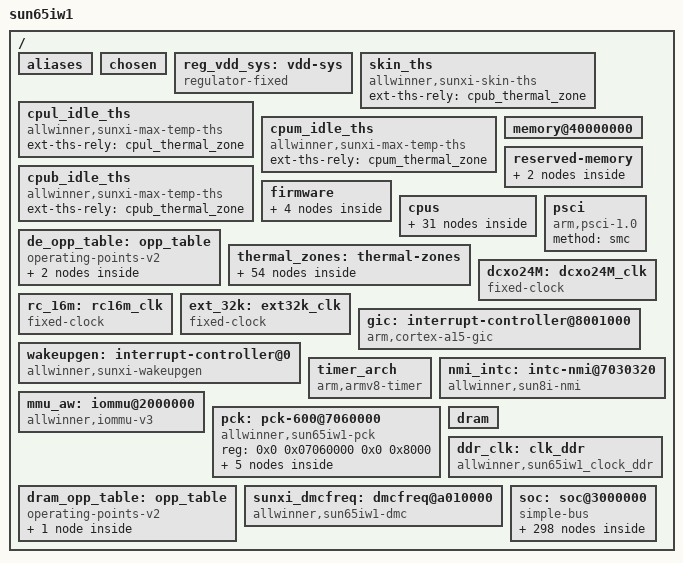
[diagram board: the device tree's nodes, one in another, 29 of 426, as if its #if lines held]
// SPDX-License-Identifier: (GPL-2.0+ or MIT)
#include <dt-bindings/clock/sun65iw1-ccu.h>
#include <dt-bindings/clock/sun65iw1-rtc.h>
#include <dt-bindings/clock/sun65iw1-r-ccu.h>
#include <dt-bindings/clock/sun65iw1-cpupll-ccu.h>
#include <dt-bindings/clock/sun65iw1-ddrpll-ccu.h>
#include <dt-bindings/clock/sunxi-ccu.h>
#include <dt-bindings/gpio/gpio.h>
#include <dt-bindings/gpio/sun4i-gpio.h>
#include <dt-bindings/reset/sun65iw1-ccu.h>
#include <dt-bindings/reset/sun65iw1-r-ccu.h>
#include <dt-bindings/power/sun65iw1-power.h>
#include <dt-bindings/interrupt-controller/arm-gic.h>
#include <dt-bindings/phy/phy.h>
#include <dt-bindings/thermal/thermal.h>
#include <dt-bindings/display/sunxi-lcd.h>
#include <dt-bindings/spi/sunxi-spi.h>
#include <dt-bindings/usb/pd.h>
#include "sun65iw1p1-vf.dtsi"

/ {
	model = "sun65iw1";
	interrupt-parent = <&wakeupgen>;
	#address-cells = <2>;
	#size-cells = <2>;

	aliases {
		serial0 = &uart0;
		serial1 = &uart1;
		serial2 = &uart2;
		serial3 = &uart3;
		serial4 = &uart4;
		serial5 = &uart5;
		serial6 = &uart6;
		serial7 = &uart7;
		serial8 = &uart8;
		serial9 = &uart9;
		ir0 = &ir_rx;
		ir1 = &s_ir_rx;
		spi0 = &spi0;
		spi1 = &spi1;
		spi2 = &spi2;
		spi3 = &r_spi0;
		twi0 = &twi0;
		twi1 = &twi1;
		twi2 = &twi2;
		twi3 = &twi3;
		twi4 = &twi4;
		twi5 = &twi5;
		twi6 = &s_twi0;
		twi7 = &s_twi1;
		twi8 = &s_twi2;
		pwm0 = &pwm0;
		pwm1 = &s_pwm0;
		ethernet0 = &gmac0;
		sunxi-mmc0 = &sdc0;
		sunxi-mmc2 = &sdc2;
		gpadc0 = &gpadc0;
		ve0 = &ve;
	};

	chosen {
		bootargs = "earlyprintk=sunxi-uart,0x2500000 loglevel=8 initcall_debug=0 console=ttyS0 init=/init";
		linux,initrd-start = <0x0 0x0>;
		linux,initrd-end = <0x0 0x0>;
		rng-seed;   /* This random value should be provided by bootloader */
		kaslr-seed; /* This random value should be provided by bootloader */
	};

	reg_vdd_sys: vdd-sys {
		compatible = "regulator-fixed";
		regulator-name = "vdd_sys";
		regulator-min-microvolt = <900000>;
		regulator-max-microvolt = <900000>;
		regulator-boot-on;
		regulator-always-on;
	};

	skin_ths: skin_ths {
		compatible = "allwinner,sunxi-skin-ths";
		ext-ths-rely = <&cpub_thermal_zone>;
		#thermal-sensor-cells = <0>;
		status = "okay";
	};

	cpul_idle_ths: cpul_idle_ths {
		compatible = "allwinner,sunxi-max-temp-ths";
		ext-ths-rely = <&cpul_thermal_zone>;
		#thermal-sensor-cells = <0>;
		status = "okay";
	};

	cpum_idle_ths: cpum_idle_ths {
		compatible = "allwinner,sunxi-max-temp-ths";
		ext-ths-rely = <&cpum_thermal_zone>;
		#thermal-sensor-cells = <0>;
		status = "okay";
	};

	cpub_idle_ths: cpub_idle_ths {
		compatible = "allwinner,sunxi-max-temp-ths";
		ext-ths-rely = <&cpub_thermal_zone>;
		#thermal-sensor-cells = <0>;
		status = "okay";
	};

	/* avoid panic when memory-node err(from uboot) */
	memory@40000000 {
		device_type = "memory";
		reg = <0x00000000 0x40000000 0x00000000 0x20000000>;
	};

	reserved-memory {
		#address-cells = <2>;
		#size-cells = <2>;
		ranges;

		bl31 {
			reg = <0x0 0x48000000 0x0 0x01000000>;
		};

#ifdef CONFIG_AW_DRM_DYNAMIC_REGION
		/*
		 * A 150MB memory region located below the 2GB address in DDR, with 4MB-aligned addr and size.
		 * start = (0x40000000+2G-152M), size = 152M.
		 * NOTE: Keep in sync with the param 'dram_region_mbytes' in sys_config.fex.
		 */
		drm_region: cma@b6800000 {
			compatible = "shared-dma-pool", "restricted-dma-pool";
			reg = <0x0 0xb6800000 0x0 0x9800000>;
			reusable;
		};
#endif
	};

	firmware {
		android {
			compatible = "android,firmware";
			name = "android";
			boot_devices = "soc@3000000/4008000.sdmmc,soc@3000000/400a000.sdmmc,soc@3000000";
			vbmeta {
				compatible = "android,vbmeta";
				parts = "vbmeta,vbmeta_system,vbmeta_vendor,boot,init_boot";
			};
		};

		optee {
			compatible = "linaro,optee-tz";
			method = "smc";
		};

#ifdef CONFIG_AW_DRM_DYNAMIC_REGION
		drm_heap_0: drm_heap {
			compatible = "allwinner,sunxi-drm-heap-v2";
			memory-region = <&drm_region>;
		};
#endif
	};

	cpus {
		#address-cells = <2>;
		#size-cells = <0>;

		cpu0: cpu@0 {
			device_type = "cpu";
			compatible = "arm,cortex-a53";
			reg = <0x0 0x0>;
			enable-method = "psci";
			next-level-cache = <&A53_L2_0>;
			cpu-idle-states = <&CLUSTER_SLEEP_0>;
			capacity-dmips-mhz = <592>;
			clocks = <&cpupll_ccu CLK_PLL_CPU0>;
			operating-points-v2 = <&cluster0_opp_table>;
			#cooling-cells = <2>;
			dynamic-power-coefficient = <57>;
		};

		cpu1: cpu@1 {
			device_type = "cpu";
			compatible = "arm,cortex-a53";
			reg = <0x0 0x1>;
			enable-method = "psci";
			next-level-cache = <&A53_L2_0>;
			cpu-idle-states = <&CLUSTER_SLEEP_0>;
			capacity-dmips-mhz = <592>;
			clocks = <&cpupll_ccu CLK_PLL_CPU0>;
			operating-points-v2 = <&cluster0_opp_table>;
			#cooling-cells = <2>;
		};

		cpu2: cpu@2 {
			device_type = "cpu";
			compatible = "arm,cortex-a53";
			reg = <0x0 0x2>;
			enable-method = "psci";
			next-level-cache = <&A53_L2_0>;
			cpu-idle-states = <&CLUSTER_SLEEP_0>;
			capacity-dmips-mhz = <592>;
			clocks = <&cpupll_ccu CLK_PLL_CPU0>;
			operating-points-v2 = <&cluster0_opp_table>;
			#cooling-cells = <2>;

			cpu2_idle: thermal-idle {
				#cooling-cells = <2>;
				duration-us = <10000>;
				exit-latency-us = <500>;
			};
		};

		cpu3: cpu@3 {
			device_type = "cpu";
			compatible = "arm,cortex-a53";
			reg = <0x0 0x3>;
			enable-method = "psci";
			next-level-cache = <&A53_L2_0>;
			cpu-idle-states = <&CLUSTER_SLEEP_0>;
			capacity-dmips-mhz = <592>;
			clocks = <&cpupll_ccu CLK_PLL_CPU0>;
			operating-points-v2 = <&cluster0_opp_table>;
			#cooling-cells = <2>;

			cpu3_idle: thermal-idle {
				#cooling-cells = <2>;
				duration-us = <10000>;
				exit-latency-us = <500>;
			};
		};

		cpu4: cpu@100 {
			device_type = "cpu";
			compatible = "arm,cortex-a53";
			reg = <0x0 0x100>;
			enable-method = "psci";
			next-level-cache = <&A53_L2_1>;
			cpu-idle-states = <&CLUSTER_SLEEP_0>;
			capacity-dmips-mhz = <592>;
			clocks = <&cpupll_ccu CLK_PLL_CPU1>;
			operating-points-v2 = <&cluster1_opp_table>;
			#cooling-cells = <2>;
			dynamic-power-coefficient = <60>;

			cpu4_idle: thermal-idle {
				#cooling-cells = <2>;
				duration-us = <10000>;
				exit-latency-us = <500>;
			};
		};

		cpu5: cpu@101 {
			device_type = "cpu";
			compatible = "arm,cortex-a53";
			reg = <0x0 0x101>;
			enable-method = "psci";
			next-level-cache = <&A53_L2_1>;
			cpu-idle-states = <&CLUSTER_SLEEP_0>;
			capacity-dmips-mhz = <592>;
			clocks = <&cpupll_ccu CLK_PLL_CPU1>;
			operating-points-v2 = <&cluster1_opp_table>;
			#cooling-cells = <2>;

			cpu5_idle: thermal-idle {
				#cooling-cells = <2>;
				duration-us = <10000>;
				exit-latency-us = <500>;
			};
		};

		cpu6: cpu@200 {
			device_type = "cpu";
			compatible = "arm,cortex-a73";
			reg = <0x0 0x200>;
			enable-method = "psci";
			next-level-cache = <&A73_L2>;
			cpu-idle-states = <&CLUSTER_SLEEP_0>;
			capacity-dmips-mhz = <1024>;
			clocks = <&cpupll_ccu CLK_PLL_CPU2>;
			operating-points-v2 = <&cluster2_opp_table>;
			#cooling-cells = <2>;
			dynamic-power-coefficient = <226>;

			cpu6_idle: thermal-idle {
				#cooling-cells = <2>;
				duration-us = <10000>;
				exit-latency-us = <500>;
			};
		};

		cpu7: cpu@201 {
			device_type = "cpu";
			compatible = "arm,cortex-a73";
			reg = <0x0 0x201>;
			enable-method = "psci";
			next-level-cache = <&A73_L2>;
			cpu-idle-states = <&CLUSTER_SLEEP_0>;
			capacity-dmips-mhz = <1024>;
			clocks = <&cpupll_ccu CLK_PLL_CPU2>;
			operating-points-v2 = <&cluster2_opp_table>;
			#cooling-cells = <2>;

			cpu7_idle: thermal-idle {
				#cooling-cells = <2>;
				duration-us = <10000>;
				exit-latency-us = <500>;
			};
		};

		cpu-map {
			cluster0 {
				core0 {
					cpu = <&cpu0>;
				};
				core1 {
					cpu = <&cpu1>;
				};
				core2 {
					cpu = <&cpu2>;
				};
				core3 {
					cpu = <&cpu3>;
				};
			};

			cluster1 {
				core0 {
					cpu = <&cpu4>;
				};
				core1 {
					cpu = <&cpu5>;
				};
			};

			cluster2 {
				core0 {
					cpu = <&cpu6>;
				};
				core1 {
					cpu = <&cpu7>;
				};
			};
		};

		idle-states {
			entry-method = "arm,psci";

			CLUSTER_SLEEP_0: cluster-sleep-0 {
				compatible = "arm,idle-state";
				arm,psci-suspend-param = <0x1010000>;
				entry-latency-us = <47>;
				exit-latency-us = <74>;
				min-residency-us = <5000>;
				local-timer-stop;
			};
		};

		A53_L2_0: l2-cache0 {
			compatible = "cache";
			cache-level = <2>;
			cache-unified;
		};

		A53_L2_1: l2-cache1 {
			compatible = "cache";
			cache-level = <2>;
			cache-unified;
		};

		A73_L2: l2-cache2 {
			compatible = "cache";
			cache-level = <2>;
			cache-unified;
		};
	};

	de_opp_table: opp_table {
		compatible = "operating-points-v2";

		opp@50000000 {
			opp-hz = /bits/ 64 <50000000>;
			opp-microvolt = <900000>;
		};

		opp@600000000 {
			opp-hz = /bits/ 64 <600000000>;
			opp-microvolt = <900000>;
		};
	};

	thermal_zones: thermal-zones {
		cpul_thermal_zone: cpul_thermal_zone {
			polling-delay-passive = <100>;
			polling-delay = <1000>;
			thermal-sensors = <&ths 0>;
			sustainable-power = <504>;

			cpul_trips: trips {
				cpul_threshold: trip-point@0 {
					temperature = <70000>;
					type = "passive";
					hysteresis = <2000>;
				};
				cpul_target: trip-point@1 {
					temperature = <90000>;
					type = "passive";
					hysteresis = <2000>;
				};
				cpul_crit: cpu_crit@0 {
					temperature = <110000>;
					type = "critical";
					hysteresis = <0>;
				};
			};

			cooling-maps {
				map0 {
					trip = <&cpul_target>;
					cooling-device = <&cpu0 THERMAL_NO_LIMIT THERMAL_NO_LIMIT>;
					contribution = <1024>;
				};
			};
		};

		cpum_thermal_zone: cpum_thermal_zone {
			polling-delay-passive = <100>;
			polling-delay = <1000>;
			thermal-sensors = <&ths 1>;
			sustainable-power = <210>;

			cpum_trips: trips {
				cpum_threshold: trip-point@0 {
					temperature = <70000>;
					type = "passive";
					hysteresis = <2000>;
				};
				cpum_target: trip-point@1 {
					temperature = <90000>;
					type = "passive";
					hysteresis = <2000>;
				};
				cpum_crit: cpu_crit@0 {
					temperature = <110000>;
					type = "critical";
					hysteresis = <0>;
				};
			};

			cooling-maps {
				map0 {
					trip = <&cpum_target>;
					cooling-device = <&cpu4 THERMAL_NO_LIMIT THERMAL_NO_LIMIT>;
					contribution = <1024>;
				};
			};
		};

		cpub_thermal_zone: cpub_thermal_zone {
			polling-delay-passive = <100>;
			polling-delay = <1000>;
			thermal-sensors = <&ths 2>;
			sustainable-power = <914>;

			cpub_trips: trips {
				cpub_threshold: trip-point@0 {
					temperature = <70000>;
					type = "passive";
					hysteresis = <2000>;
				};
				cpub_target: trip-point@1 {
					temperature = <90000>;
					type = "passive";
					hysteresis = <2000>;
				};
				cpub_crit: cpu_crit@0 {
					temperature = <110000>;
					type = "critical";
					hysteresis = <0>;
				};
			};

			cooling-maps {
				map0 {
					trip = <&cpub_target>;
					cooling-device = <&cpu6 THERMAL_NO_LIMIT THERMAL_NO_LIMIT>;
					contribution = <1024>;
				};
			};
		};

		gpu_thermal_zone: gpu_thermal_zone {
			polling-delay-passive = <100>;
			polling-delay = <1000>;
			thermal-sensors = <&ths 3>;

			gpu_trips: trips {
				gpu_threshold: trip-point@0 {
					temperature = <70000>;
					type = "passive";
					hysteresis = <0>;
				};
				gpu_target: trip-point@1 {
					temperature = <90000>;
					type = "passive";
					hysteresis = <0>;
				};
				gpu_crit: gpu_crit@0 {
					temperature = <110000>;
					type = "critical";
					hysteresis = <0>;
				};
			};

			cooling-maps {
				map0 {
					trip = <&gpu_threshold>;
					cooling-device = <&gpu 0 0>;
					contribution = <1024>;
				};
				map1 {
					trip = <&gpu_target>;
					cooling-device = <&gpu 0 THERMAL_NO_LIMIT>;
					contribution = <1024>;
				};
				map2 {
					trip = <&gpu_crit>;
					cooling-device = <&gpu THERMAL_NO_LIMIT THERMAL_NO_LIMIT>;
					contribution = <1024>;
				};
			};
		};

		ddr_thermal_zone: ddr_thermal_zone {
			polling-delay-passive = <100>;
			polling-delay = <1000>;
			thermal-sensors = <&ths 4>;

			ddr_trips: trips {
				ddr_crit: ddr_crit@0 {
					temperature = <110000>;
					type = "critical";
					hysteresis = <0>;
				};
			};
		};

		skin_zone: skin_zone {
			polling-delay-passive = <0>;
			polling-delay = <0>;
			thermal-sensors = <&skin_ths>;

			skin_trips: trips {
				skin_crit: skin_crit@0 {
					temperature = <50000>;
					type = "critical";
					hysteresis = <0>;
				};
			};
		};

		cpul_idle_zone: cpul_idle_zone {
			polling-delay-passive = <100>;
			polling-delay = <1000>;
			thermal-sensors = <&cpul_idle_ths>;

			cpul_idle_trips: trips {
				cpul_thres: trip-point@0 {
					temperature = <90000>;
					type = "passive";
					hysteresis = <2000>;
				};
				cpul_overshot: trip-point@1{
					temperature = <100000>;
					type = "passive";
					hysteresis = <2000>;
				};
			};

			cooling-maps {
				map0 {
					trip = <&cpul_overshot>;
					cooling-device = <&cpu2_idle 0 50>,
							 <&cpu3_idle 0 50>;
					contribution = <1024>;
				};
			};
		};

		cpum_idle_zone: cpum_idle_zone {
			polling-delay-passive = <100>;
			polling-delay = <1000>;
			thermal-sensors = <&cpum_idle_ths>;

			cpum_idle_trips: trips {
				cpum_thres: trip-point@0 {
					temperature = <90000>;
					type = "passive";
					hysteresis = <2000>;
				};
				cpum_overshot: trip-point@1{
					temperature = <100000>;
					type = "passive";
					hysteresis = <2000>;
				};
			};

			cooling-maps {
				map0 {
					trip = <&cpum_overshot>;
					cooling-device = <&cpu4_idle 0 50>,
							 <&cpu5_idle 0 50>;
					contribution = <1024>;
				};
			};
		};

		cpub_idle_zone: cpub_idle_zone {
			polling-delay-passive = <100>;
			polling-delay = <1000>;
			thermal-sensors = <&cpub_idle_ths>;

			cpub_idle_trips: trips {
				cpub_thres: trip-point@0 {
					temperature = <90000>;
					type = "passive";
					hysteresis = <2000>;
				};
				cpub_overshot: trip-point@1{
					temperature = <100000>;
					type = "passive";
					hysteresis = <2000>;
				};
			};

			cooling-maps {
				map0 {
					trip = <&cpub_overshot>;
					cooling-device = <&cpu6_idle 0 100>,
							 <&cpu7_idle 0 100>;
					contribution = <1024>;
				};
			};
		};
	};

	psci {
		compatible = "arm,psci-1.0";
		method = "smc";
	};

	dcxo24M: dcxo24M_clk {
		#clock-cells = <0>;
		compatible = "fixed-clock";
		clock-frequency = <24000000>;
		clock-output-names = "dcxo24M";
	};

	rc_16m: rc16m_clk {
		#clock-cells = <0>;
		compatible = "fixed-clock";
		clock-frequency = <16000000>;
		clock-accuracy = <300000000>;
		clock-output-names = "rc-16m";
	};

	ext_32k: ext32k_clk {
		#clock-cells = <0>;
		compatible = "fixed-clock";
		clock-frequency = <32768>;
		clock-output-names = "ext-32k";
	};

	gic: interrupt-controller@8001000{
		compatible = "arm,cortex-a15-gic", "arm,cortex-a9-gic";
		#interrupt-cells = <3>;
		#address-cells = <0>;
		device_type = "gic";
		interrupt-controller;
		reg = <0x0 0x08001000 0 0x1000>, /* GIC Dist */
			<0x0 0x08002000 0 0x2000>, /* GIC CPU */
			<0x0 0x08004000 0 0x2000>, /* GIC VCPU Control */
			<0x0 0x08006000 0 0x2000>; /* GIC VCPU */
		interrupts = <GIC_PPI 9 0xf04>; /* GIC Maintenence IRQ */
		interrupt-parent = <&gic>;
	};

	wakeupgen: interrupt-controller@0 {
		compatible = "allwinner,sunxi-wakeupgen";
		interrupt-controller;
		#interrupt-cells = <3>;
		#address-cells = <0>;
		interrupt-parent = <&gic>;
	};

	timer_arch {
		compatible = "arm,armv8-timer";
		interrupts = <GIC_PPI 13 (GIC_CPU_MASK_SIMPLE(4) | IRQ_TYPE_LEVEL_LOW)>,
			     <GIC_PPI 14 (GIC_CPU_MASK_SIMPLE(4) | IRQ_TYPE_LEVEL_LOW)>,
			     <GIC_PPI 11 (GIC_CPU_MASK_SIMPLE(4) | IRQ_TYPE_LEVEL_LOW)>,
			     <GIC_PPI 10 (GIC_CPU_MASK_SIMPLE(4) | IRQ_TYPE_LEVEL_LOW)>;
		clock-frequency = <24000000>;
		interrupt-parent = <&gic>;
		arm,no-tick-in-suspend;
	};

	nmi_intc: intc-nmi@7030320 {
		compatible = "allwinner,sun8i-nmi";
		interrupt-parent = <&gic>;
		#interrupt-cells = <2>;
		#address-cells = <0>;
		interrupt-controller;
		reg = <0x0 0x07030320 0 0xc>;
		interrupts = <GIC_SPI 224 IRQ_TYPE_LEVEL_HIGH>;
	};

	mmu_aw: iommu@2000000 {
		compatible = "allwinner,iommu-v3";
		reg = <0x0 0x02000000 0x0 0x1000>;
		interrupts = <GIC_SPI 91 IRQ_TYPE_LEVEL_HIGH>;
		interrupt-names = "iommu-irq";
		clocks = <&ccu CLK_BUS_IOMMU_APB>;
		clock-names = "iommu";
		/* clock-frequency = <24000000>; */
		#iommu-cells = <2>;
		version=<0x17>;
		tlb_prefetch = <0x3007f>;
		tlb_invalid_mode = <0x1>;
		ptw_invalid_mode = <0x1>;
		masters = "ISP", "CSI", "VE0", "Eink", "G2D",
			"DE", "RESERVED", "DEBUG_MODE";
		valid_masters=<7>;
	};

	pck: pck-600@7060000 {
		compatible = "allwinner,sun65iw1-pck", "syscon", "simple-mfd";
		reg = <0x0 0x07060000 0x0 0x8000>;

		pd: power-controller {
			compatible = "allwinner,sun65iw1-pck-600";
			clocks = <&r_ccu CLK_BUS_R_PPU_VO0>;
			clock-names = "pck";
			#power-domain-cells = <1>;
			#address-cells = <1>;
			#size-cells = <0>;

			pd_vo@SUN65IW1_PCK_VO {
				reg = <SUN65IW1_PCK_VO>;
			};

			pd_ve@SUN65IW1_PCK_VE {
				reg = <SUN65IW1_PCK_VE>;
			};

			pd_vi@SUN65IW1_PCK_VI {
				reg = <SUN65IW1_PCK_VI>;
			};

			pd_hsi@SUN65IW1_PCK_HSI {
				reg = <SUN65IW1_PCK_HSI>;
			};
		};
	};

	dram: dram {
		/* for uboot update dram para */
		dram_para00 = <0x00000000>;
		dram_para01 = <0x00000000>;
		dram_para02 = <0x00000000>;
		dram_para03 = <0x00000000>;
		dram_para04 = <0x00000000>;
		dram_para05 = <0x00000000>;
		dram_para06 = <0x00000000>;
		dram_para07 = <0x00000000>;
		dram_para08 = <0x00000000>;
		dram_para09 = <0x00000000>;
		dram_para10 = <0x00000000>;
		dram_para11 = <0x00000000>;
		dram_para12 = <0x00000000>;
		dram_para13 = <0x00000000>;
		dram_para14 = <0x00000000>;
		dram_para15 = <0x00000000>;
		dram_para16 = <0x00000000>;
		dram_para17 = <0x00000000>;
		dram_para18 = <0x00000000>;
		dram_para19 = <0x00000000>;
		dram_para20 = <0x00000000>;
		dram_para21 = <0x00000000>;
		dram_para22 = <0x00000000>;
		dram_para23 = <0x00000000>;
		dram_para24 = <0x00000000>;
		dram_para25 = <0x00000000>;
		dram_para26 = <0x00000000>;
		dram_para27 = <0x00000000>;
		dram_para28 = <0x00000000>;
		dram_para29 = <0x00000000>;
		dram_para30 = <0x00000000>;
		dram_para31 = <0x00000000>;
		dram_para32 = <0x00000000>;
		dram_para33 = <0x00000000>;
		dram_para34 = <0x00000000>;
		dram_para35 = <0x00000000>;
		dram_para36 = <0x00000000>;
		dram_para37 = <0x00000000>;
		dram_para38 = <0x00000000>;
		dram_para39 = <0x00000000>;
		dram_para40 = <0x00000000>;
		dram_para41 = <0x00000000>;
		dram_para42 = <0x00000000>;
		dram_para43 = <0x00000000>;
		dram_para44 = <0x00000000>;
		dram_para45 = <0x00000000>;
		dram_para46 = <0x00000000>;
		dram_para47 = <0x00000000>;
		dram_para48 = <0x00000000>;
		dram_para49 = <0x00000000>;
		dram_para50 = <0x00000000>;
		dram_para51 = <0x00000000>;
		dram_para52 = <0x00000000>;
		dram_para53 = <0x00000000>;
		dram_para54 = <0x00000000>;
		dram_para55 = <0x00000000>;
		dram_para56 = <0x00000000>;
		dram_para57 = <0x00000000>;
		dram_para58 = <0x00000000>;
		dram_para59 = <0x00000000>;
		dram_para60 = <0x00000000>;
		dram_para61 = <0x00000000>;
		dram_para62 = <0x00000000>;
		dram_para63 = <0x00000000>;
		dram_para64 = <0x00000000>;
		dram_para65 = <0x00000000>;
		dram_para66 = <0x00000000>;
		dram_para67 = <0x00000000>;
		dram_para68 = <0x00000000>;
		dram_para69 = <0x00000000>;
		dram_para70 = <0x00000000>;
		dram_para71 = <0x00000000>;
		dram_para72 = <0x00000000>;
		dram_para73 = <0x00000000>;
		dram_para74 = <0x00000000>;
		dram_para75 = <0x00000000>;
		dram_para76 = <0x00000000>;
		dram_para77 = <0x00000000>;
		dram_para78 = <0x00000000>;
		dram_para79 = <0x00000000>;
		dram_para80 = <0x00000000>;
		dram_para81 = <0x00000000>;
		dram_para82 = <0x00000000>;
		dram_para83 = <0x00000000>;
		dram_para84 = <0x00000000>;
		dram_para85 = <0x00000000>;
		dram_para86 = <0x00000000>;
		dram_para87 = <0x00000000>;
		dram_para88 = <0x00000000>;
		dram_para89 = <0x00000000>;
		dram_para90 = <0x00000000>;
		dram_para91 = <0x00000000>;
		dram_para92 = <0x00000000>;
		dram_para93 = <0x00000000>;
		dram_para94 = <0x00000000>;
		dram_para95 = <0x00000000>;
	};

	ddr_clk: clk_ddr {
		compatible = "allwinner,sun65iw1_clock_ddr";
		reg = <0x0 0x0a030000 0x0 0x1000>,
				<0x0 0x0a011000 0x0 0x1000>;
		clocks = <&drampll_ccu CLK_DFI>,
				<&drampll_ccu CLK_PLL_DDR0>,
				<&drampll_ccu CLK_PLL_DDR1>,
				<&drampll_ccu CLK_PLL_DDR2>;
		clock-names = "dfi_clk", "ddrpll0", "ddrpll1", "ddrpll2";
		#clock-cells = <0>;
	};

	dram_opp_table: opp_table {
		compatible = "operating-points-v2";
		opp@150000000 {
			opp-hz = /bits/ 64 <150000000>;
			clock-latency-ns = <150000>;
			opp-microvolt = <900000>;
		};
	};

	sunxi_dmcfreq: dmcfreq@a010000 {
		compatible = "allwinner,sun65iw1-dmc";
		reg = <0x0 0x0a010000 0x0 0x11000>,
			  <0x0 0x02400000 0x0 0x3000>;
		interrupts = <GIC_SPI 88 IRQ_TYPE_LEVEL_HIGH>;
		clocks = <&ddr_clk>,
				<&ccu CLK_NSI>,
				<&drampll_ccu CLK_PLL_DDR0>,
				<&drampll_ccu CLK_PLL_DDR1>,
				<&drampll_ccu CLK_PLL_DDR2>;
		clock-names = "dram", "bus", "ddrpll0", "ddrpll1", "ddrpll2";
		operating-points-v2 = <&dram_opp_table>;
		upthreshold = <30>;
		downdifferential = <15>;
		vddcore-supply = <&reg_vdd_sys>;
		normalvoltage = <900000>;
		boostvoltage = <900000>;
	};

	soc: soc@3000000 {
		compatible = "simple-bus";
		#address-cells = <2>;
		#size-cells = <2>;
		ranges;

		cpufreq_hw: cpufreq@7010000 {
			compatible = "allwinner,sun65iw1-hw-dvfs";
			reg = <0 0x07010000 0 0x64>, <0 0x07010200 0 0x64>, <0 0x07010100 0 0x64>;
			reg-names = "cluster0-dvfs", "cluster1-dvfs", "cluster2-dvfs";
			clocks = <&cpupll_ccu CLK_PLL_CPU0>, <&cpupll_ccu CLK_PLL_CPU1>, <&cpupll_ccu CLK_PLL_CPU2>;
			#freq-domain-cells = <2>;
			dvfs_twi = <&s_twi0>;
			pmu_addr = <0x35 0x36 0x36>; //0x68 0x6c 0x6c
			pmu_reg_addr = <0x83 0x14 0x13>;
			twi_priority = <0 0 0>;
			twi_mask = <0x80 0x80 0x00>;
			channel = <0 1 2>;
			twi_channel_num = <3>;
			cluster0-supply = <&reg_dcdc1>;
			cluster1-supply = <&reg_axp1530_dcdc2>;
			cluster2-supply = <&reg_axp1530_dcdc1>;
		};

		rtc_ccu: rtc_ccu@7200000 {
			compatible = "allwinner,sun65iw1-rtc-ccu";
			reg = <0x0 0x07200000 0x0 0x400>;
			#clock-cells = <1>;
			#reset-cells = <1>;
		};

		cpupll_ccu: clock@8200000 {
			compatible = "allwinner,sun65iw1-cpupll";
			reg = <0x0 0x08200000 0x0 0x050c>;
			#clock-cells = <1>;
			#reset-cells = <1>;
			pll_step = <0x9>;
			pll_ssc = <0x3300>;
		};

		ccu: ccu@3008000 {
			compatible = "allwinner,sun65iw1-ccu";
			reg = <0x0 0x03008000 0x0 0x2000>;
			clocks = <&dcxo24M>, <&rtc_ccu CLK_OSC32K>, <&rc_16m>;
			clock-names = "hosc", "losc", "iosc";
			#clock-cells = <1>;
			#reset-cells = <1>;
		       /*
			* for example:
			* sdm_info: sdm_info {
			*	pll-video0-parent {
			*		sdm-enable = <1>; // required
			*		sdm-factor = <4>; // required
			*		freq-mode  = <TR_N>; // optional: default TR_N
			*		sdm-freq   = <FREQ_32>; // optional: default FREQ_31_5
			*	};
			* };
			*/
		};

		r_ccu: r_ccu@7030000 {
			compatible = "allwinner,sun65iw1-r-ccu";
			reg = <0x0 0x07030000 0x0 0x230>;
			#clock-cells = <1>;
			#reset-cells = <1>;
		};

		drampll_ccu: drampll_ccu@A030000 {
			compatible = "allwinner,sun65iw1-pll-dram";
			reg = <0x0 0x0A030000 0x0 0x1000>;
			#clock-cells = <1>;
			#reset-cells = <1>;
		};


		pd_vo_pwrctl: pd_vo_pwrctl@0 {
			compatible = "allwinner,sunxi-power-domain-power-ctl";
			power-domains = <&pd SUN65IW1_PCK_VO>;
			status = "okay";
		};

		pd_ve_pwrctl: pd_ve_pwrctl@0 {
			compatible = "allwinner,sunxi-power-domain-power-ctl";
			power-domains = <&pd SUN65IW1_PCK_VE>;
			status = "okay";
		};

		pd_vi_pwrctl: pd_vi_pwrctl@0 {
			compatible = "allwinner,sunxi-power-domain-power-ctl";
			power-domains = <&pd SUN65IW1_PCK_VI>;
			status = "okay";
		};

		/*
		pd_hsi_pwrctl: pd_hsi_pwrctl@0 {
			compatible = "allwinner,sunxi-power-domain-power-ctl";
			power-domains = <&pd SUN65IW1_PCK_HSI>;
			status = "okay";
		};
		*/

		ve: ve@1c0e000 {
			compatible = "allwinner,sunxi-cedar-ve";
			reg = <0x0 0x01c0e000 0x0 0x1000>,
				  <0x0 0x03200000 0x0 0x10>;
			interrupts = <GIC_SPI 182 IRQ_TYPE_LEVEL_HIGH>;
			clocks = <&ccu CLK_PLL_VE>,
				 <&ccu CLK_MBUS_VE0>,
				 <&ccu CLK_BUS_VE0_AHB_SW>,
				 <&ccu CLK_VE0_MBUS_GATE>,
				 <&ccu CLK_VE0>,
				 <&ccu CLK_BUS_VE0_AHB>;
			clock-names = "pll_ve",
				      "mbus_ve",
				      "ahb_gate",
				      "mbus_gate",
				      "ve",
				      "bus_ve";
			resets = <&ccu RST_BUS_VE0>;
			reset-names = "reset_ve";
			operating-points-v2 = <&ve_opp_table>;
			iommus = <&mmu_aw 2 1>;
			power-domains = <&pd SUN65IW1_PCK_VE>;
		};

		pio: pinctrl@3000000 {
			compatible = "allwinner,sun65iw1-pinctrl";
			reg = <0x0 0x03000000 0x0 0x800>;
			interrupts = <GIC_SPI 126 IRQ_TYPE_LEVEL_HIGH>,
				     <GIC_SPI 128 IRQ_TYPE_LEVEL_HIGH>,
				     <GIC_SPI 130 IRQ_TYPE_LEVEL_HIGH>,
				     <GIC_SPI 132 IRQ_TYPE_LEVEL_HIGH>,
				     <GIC_SPI 134 IRQ_TYPE_LEVEL_HIGH>,
				     <GIC_SPI 136 IRQ_TYPE_LEVEL_HIGH>,
				     <GIC_SPI 138 IRQ_TYPE_LEVEL_HIGH>,
				     <GIC_SPI 144 IRQ_TYPE_LEVEL_HIGH>;
			clocks = <&ccu CLK_APB1>, <&dcxo24M>, <&rtc_ccu CLK_OSC32K>;
			clock-names = "apb", "hosc", "losc";
			gpio-controller;
			#gpio-cells = <3>;
			interrupt-controller;
			#interrupt-cells = <3>;

			sdc0_pins_f: sdc0@5 {
				pins = "PF2";
				function = "sdc0";
				drive-strength = <40>;
				bias-pull-up;
				power-source = <3300>;
			};

			sdc0_pins_g: sdc0@6 {
				pins = "PF2";
				function = "sdc0";
				drive-strength = <40>;
				bias-pull-up;
				power-source = <1800>;
			};

			sdc0_pins_a: sdc0@0 {
				pins = "PF0", "PF1",
						"PF3", "PF4", "PF5";
				function = "sdc0";
				drive-strength = <20>;
				bias-pull-up;
				power-source = <3300>;
			};

			sdc0_pins_b: sdc0@1 {
				pins = "PF0", "PF1",
						"PF3", "PF4", "PF5";
				function = "sdc0";
				drive-strength = <20>;
				bias-pull-up;
				power-source = <1800>;
			};

			sdc0_pins_c: sdc0@2 {
				pins = "PF0", "PF1", "PF2",
				"PF3", "PF4", "PF5";
				function = "gpio_in";
			};

			/* TODO: add jtag pin */
			sdc0_pins_d: sdc0@3 {
				pins = "PF2", "PF4";
				function = "uart0";
				drive-strength = <10>;
				bias-pull-up;
			};

			sdc0_pins_e: sdc0@4 {
				pins = "PF0", "PF1", "PF3",
						"PF5";
				function = "jtag";
				drive-strength = <10>;
				bias-pull-up;
			};

			sdc1_pins_a: sdc1@0 {
				pins = "PG1", "PG2",
						"PG3", "PG4", "PG5";
				function = "sdc1";
				drive-strength = <20>;
				bias-pull-up;
			};

			sdc1_pins_b: sdc1@1 {
				pins = "PG0", "PG1", "PG2",
						"PG3", "PG4", "PG5";
				function = "gpio_in";
			};

			sdc1_pins_c: sdc1@2 {
				pins = "PG0";
				function = "sdc1";
				drive-strength = <40>;
				bias-pull-up;
			};

			sdc2_pins_a: sdc2@0 {
				pins = "PC3",
					"PC4", "PC5", "PC6", "PC7",
					"PC8", "PC9", "PC10", "PC11";
				function = "sdc2";
				drive-strength = <20>;
				bias-pull-up;
			};

			sdc2_pins_b: sdc2@1 {
				pins = "PC0", "PC1", "PC2", "PC3",
						"PC4", "PC5", "PC6", "PC7",
						"PC8", "PC9", "PC10", "PC11";
				function = "gpio_in";
			};

			sdc2_pins_c: sdc2@2 {
				pins = "PC0";
				function = "sdc2";
				drive-strength = <40>;
				bias-pull-down;
			};

			sdc2_pins_d: sdc2@3 {
				pins = "PC1", "PC2";
				function = "sdc2";
				drive-strength = <40>;
				bias-pull-up;
			};

			csi_mclk0_pins_a: csi_mclk0@0 {
				pins = "PE0";
				function = "mcsi0";
				drive-strength = <20>;
			};

			csi_mclk0_pins_b: csi_mclk0@1 {
				pins = "PE0";
				function = "gpio_in";
			};

			csi_mclk1_pins_a: csi_mclk1@0 {
				pins = "PE5";
				function = "mcsi1";
				drive-strength = <20>;
			};

			csi_mclk1_pins_b: csi_mclk1@1 {
				pins = "PE5";
				function = "gpio_in";
			};

			csi_mclk2_pins_a: csi_mclk2@0 {
				pins = "PE15";
				function = "mcsi2";
				drive-strength = <20>;
			};

			csi_mclk2_pins_b: csi_mclk2@1 {
				pins = "PE15";
				function = "gpio_in";
			};

			ncsi_bt656_pins_a: ncsi_BT656@0 {
				pins = "PK10", "PK12", "PK13",
				"PK14", "PK15", "PK16", "PK17",
				"PK18", "PK19", "PK20", "PK21";
				function = "ncsi";
				drive-strength = <20>;
			};

			ncsi_bt656_pins_b: ncsi_BT656@1 {
				pins = "PK10", "PK12", "PK13",
				"PK14", "PK15", "PK16", "PK17",
				"PK18", "PK19", "PK20", "PK21";
				function = "gpio_in";
			};

			ncsi_bt1120_pins_a: ncsi_BT1120@0 {
				pins = "PK10", "PK12", "PK13",
				"PK14", "PK15", "PK16", "PK17",
				"PK18", "PK19", "PK20", "PK21",
				"PE8", "PE9", "PE10", "PE11",
				"PE12", "PE13", "PE14", "PE15";
				function = "ncsi";
				drive-strength = <20>;
			};

			ncsi_bt1120_pins_b: ncsi_BT1120@1 {
				pins = "PK10", "PK12", "PK13",
				"PK14", "PK15", "PK16", "PK17",
				"PK18", "PK19", "PK20", "PK21",
				"PE8", "PE9", "PE10", "PE11",
				"PE12", "PE13", "PE14", "PE15";
				function = "gpio_in";
			};

			mipia_pins_a: mipia@0 {
				pins = "PK0", "PK1", "PK2", "PK3", "PK4", "PK5",
					"PK6", "PK7", "PK8", "PK9";
				function = "mcsia";
				drive-strength = <10>;
			};

			mipia_pins_b: mipia@1 {
				pins = "PK0", "PK1", "PK2", "PK3", "PK4", "PK5",
					"PK6", "PK7", "PK8", "PK9";
				function = "gpio_in";
			};

			mipib_pins_a: mipib@0 {
				pins = "PK10", "PK11", "PK12",
					"PK13", "PK14", "PK15";
				function = "mcsib";
				drive-strength = <10>;
			};

			mipib_pins_b: mipib@1 {
				pins = "PK10", "PK11", "PK12",
					"PK13", "PK14", "PK15";
				function = "gpio_in";
			};

			mipic_pins_a: mipic@0 {
				pins = "PK16", "PK17", "PK18",
					"PK19", "PK20", "PK21";
				function = "mcsic";
				drive-strength = <10>;
			};

			mipic_pins_b: mipic@1 {
				pins = "PK16", "PK17", "PK18",
					"PK19", "PK20", "PK21";
				function = "gpio_in";
			};

			mipic_4lane_pins_a: mipic_4lane@0 {
				pins = "PK16", "PK17", "PK18",
					"PK19", "PK20", "PK21";
				function = "mcsic";
				drive-strength = <10>;
			};

			mipic_4lane_pins_b: mipic_4lane@1 {
				pins = "PK16", "PK17", "PK18",
					"PK19", "PK20", "PK21";
				function = "gpio_in";
			};

			dsi0_4lane_pins_a: dsi0_4lane@0 {
				pins = "PD0", "PD1", "PD2", "PD3", "PD4", "PD5", "PD6", "PD7", "PD8", "PD9";
				function = "dsi0";
				drive-strength = <30>;
				bias-disable;
			};

			dsi0_4lane_pins_b: dsi0_4lane@1 {
				pins = "PD0", "PD1", "PD2", "PD3", "PD4", "PD5", "PD6", "PD7", "PD8", "PD9";
				function = "io_disabled";
				bias-disable;
			};

			lvds0_pins_a: lvds0@0 {
				pins = "PD0", "PD1", "PD2", "PD3", "PD4", "PD5", "PD6", "PD7", "PD8", "PD9";
				function = "lvds0";
				drive-strength = <30>;
			};

			lvds0_pins_b: lvds0@1 {
				pins = "PD0", "PD1", "PD2", "PD3", "PD4", "PD5", "PD6", "PD7", "PD8", "PD9";
				function = "gpio_in";
			};

			lvds1_pins_a: lvds1@0 {
				pins = "PD10", "PD11", "PD12", "PD13", "PD14", "PD15", "PD16", "PD17", "PD18", "PD19";
				function = "lvds1";
				drive-strength = <30>;
			};

			lvds1_pins_b: lvds1@1 {
				pins = "PD10", "PD11", "PD12", "PD13", "PD14", "PD15", "PD16", "PD17", "PD18", "PD19";
				function = "gpio_in";
			};

			rgb0_24pins_a: rgb0@0 {
				pins = "PH8", "PH9", "PD0", "PD1", "PD2", "PD3", "PD4", "PD5", "PH10", "PH13", "PD6", "PD7", "PD8", "PD9", \
					"PD10", "PD11", "PH14", "PH15", "PD12", "PD13", "PD14", "PD15", "PD16", "PD17", "PD18", "PD19", \
					"PD20", "PD21";
				function = "lcd0";
				drive-strength = <30>;
			};

			rgb0_24pins_b: rgb0@1 {
				pins = "PH8", "PH9", "PD0", "PD1", "PD2", "PD3", "PD4", "PD5", "PH10", "PH13", "PD6", "PD7", "PD8", "PD9", \
					"PD10", "PD11", "PH14", "PH15", "PD12", "PD13", "PD14", "PD15", "PD16", "PD17", "PD18", "PD19", \
					"PD20", "PD21";
				function = "gpio_in";
			};
		};

		r_pio: pinctrl@7058000 {
			#address-cells = <1>;
			compatible = "allwinner,sun65iw1-r-pinctrl";
			reg = <0x0 0x07058000 0x0 0x200>;
			interrupts = <GIC_SPI 234 IRQ_TYPE_LEVEL_HIGH>, /* GPIOL */
				<GIC_SPI 236 IRQ_TYPE_LEVEL_HIGH>;
			clocks = <&r_ccu CLK_R_APB0>, <&dcxo24M>, <&rtc_ccu CLK_OSC32K>;
			clock-names = "apb", "hosc", "losc";
			gpio-controller;
			#gpio-cells = <3>;
			interrupt-controller;
			#interrupt-cells = <3>;
		};

		uart0: uart@2B00000 {
			compatible = "allwinner,uart-v102";
			reg = <0x0 0x02B00000 0x0 0x400>;
			interrupts = <GIC_SPI 2 IRQ_TYPE_LEVEL_HIGH>;
			clocks = <&ccu CLK_BUS_UART0_APB>;
			resets = <&ccu RST_BUS_UART0>;
			sunxi,uart-fifosize = <64>;
			uart0_port = <0>;
			uart0_type = <2>;
		};

		uart1: uart@2B01000 {
			compatible = "allwinner,uart-v102";
			device_type = "uart1";
			reg = <0x0 0x02B01000 0x0 0x400>;
			interrupts = <GIC_SPI 3 IRQ_TYPE_LEVEL_HIGH>;
			clocks = <&ccu CLK_BUS_UART1_APB>;
			resets = <&ccu RST_BUS_UART1>;
			sunxi,uart-fifosize = <128>;
			uart1_port = <1>;
			uart1_type = <4>;
			dmas = <&dma 41>,<&dma 41>;
			dma-names = "fake_tx","fake_rx";
			//dma-names = "tx","rx";
			status = "disabled";
		};

		uart2: uart@2B02000 {
			compatible = "allwinner,uart-v102";
			device_type = "uart2";
			reg = <0x0 0x02B02000 0x0 0x400>;
			interrupts = <GIC_SPI 4 IRQ_TYPE_LEVEL_HIGH>;
			clocks = <&ccu CLK_BUS_UART2_APB>;
			resets = <&ccu RST_BUS_UART2>;
			sunxi,uart-fifosize = <128>;
			uart2_port = <2>;
			uart2_type = <4>;
			dmas = <&dma 42>,<&dma 42>;
			dma-names = "fake_tx","fake_rx";
			//dma-names = "tx","rx";
			status = "disabled";
		};

		uart3: uart@2B03000 {
			compatible = "allwinner,uart-v102";
			device_type = "uart3";
			reg = <0x0 0x02B03000 0x0 0x400>;
			interrupts = <GIC_SPI 5 IRQ_TYPE_LEVEL_HIGH>;
			clocks = <&ccu CLK_BUS_UART3_APB>;
			resets = <&ccu RST_BUS_UART3>;
			sunxi,uart-fifosize = <128>;
			uart3_port = <3>;
			uart3_type = <4>;
			dmas = <&dma 43>,<&dma 43>;
			dma-names = "fake_tx","fake_rx";
			//dma-names = "tx","rx";
			status = "disabled";
		};

		uart4: uart@2B04000 {
			compatible = "allwinner,uart-v102";
			device_type = "uart4";
			reg = <0x0 0x02B04000 0x0 0x400>;
			interrupts = <GIC_SPI 6 IRQ_TYPE_LEVEL_HIGH>;
			clocks = <&ccu CLK_BUS_UART4_APB>;
			resets = <&ccu RST_BUS_UART4>;
			sunxi,uart-fifosize = <128>;
			uart4_port = <4>;
			uart4_type = <4>;
			dmas = <&dma 44>,<&dma 44>;
			dma-names = "fake_tx","fake_rx";
			//dma-names = "tx","rx";
			status = "disabled";
		};

		uart5: uart@2B05000 {
			compatible = "allwinner,uart-v102";
			device_type = "uart5";
			reg = <0x0 0x02B05000 0x0 0x400>;
			interrupts = <GIC_SPI 7 IRQ_TYPE_LEVEL_HIGH>;
			clocks = <&ccu CLK_BUS_UART5_APB>;
			resets = <&ccu RST_BUS_UART5>;
			sunxi,uart-fifosize = <128>;
			uart5_port = <5>;
			uart5_type = <4>;
			dmas = <&dma 45>,<&dma 45>;
			dma-names = "fake_tx","fake_rx";
			//dma-names = "tx","rx";
			status = "disabled";
		};

		uart6: uart@2B06000 {
			compatible = "allwinner,uart-v102";
			device_type = "uart6";
			reg = <0x0 0x02B06000 0x0 0x400>;
			interrupts = <GIC_SPI 8 IRQ_TYPE_LEVEL_HIGH>;
			clocks = <&ccu CLK_BUS_UART6_APB>;
			resets = <&ccu RST_BUS_UART6>;
			sunxi,uart-fifosize = <128>;
			uart6_port = <6>;
			uart6_type = <4>;
			dmas = <&dma 46>,<&dma 46>;
			dma-names = "fake_tx","fake_rx";
			//dma-names = "tx","rx";
			status = "disabled";
		};

		uart7: uart@2B07000 {
			compatible = "allwinner,uart-v102";
			device_type = "uart7";
			reg = <0x0 0x02B07000 0x0 0x400>;
			interrupts = <GIC_SPI 9 IRQ_TYPE_LEVEL_HIGH>;
			clocks = <&ccu CLK_BUS_UART7_APB>;
			resets = <&ccu RST_BUS_UART7>;
			sunxi,uart-fifosize = <128>;
			uart7_port = <7>;
			uart7_type = <4>;
			dmas = <&dma 47>,<&dma 47>;
			dma-names = "fake_tx","fake_rx";
			//dma-names = "tx","rx";
			status = "disabled";
		};

		uart8: uart@7100000 {
			compatible = "allwinner,uart-v102";
			device_type = "uart8";
			reg = <0x0 0x07100000 0x0 0x400>;
			interrupts = <GIC_SPI 237 IRQ_TYPE_LEVEL_HIGH>;
			clocks = <&r_ccu CLK_BUS_R_UART0>;
			resets = <&r_ccu RST_BUS_R_UART0>;
			sunxi,uart-fifosize = <64>;
			uart8_port = <8>;
			uart8_type = <2>;
			dmas = <&dma 59>,<&dma 59>;
			dma-names = "fake_tx","fake_rx";
			//dma-names = "tx","rx";
			status = "disabled";
		};

		uart9: uart@7101000 {
			compatible = "allwinner,uart-v102";
			device_type = "uart9";
			reg = <0x0 0x07101000 0x0 0x400>;
			interrupts = <GIC_SPI 238 IRQ_TYPE_LEVEL_HIGH>;
			clocks = <&r_ccu CLK_BUS_R_UART1>;
			resets = <&r_ccu RST_BUS_R_UART1>;
			sunxi,uart-fifosize = <64>;
			uart9_port = <9>;
			uart9_type = <2>;
			dmas = <&dma 60>,<&dma 60>;
			dma-names = "fake_tx","fake_rx";
			//dma-names = "tx","rx";
			status = "disabled";
		};

		rtc: rtc@7200000 {
			compatible = "allwinner,rtc-v201";
			device_type = "rtc";
			wakeup-source;
			reg = <0x0 0x07200000 0x0 0x320>;
			interrupts = <GIC_SPI 232 IRQ_TYPE_LEVEL_HIGH>;
			clocks = <&r_ccu CLK_BUS_R_RTC>, <&rtc_ccu CLK_RTC_1K>, <&rtc_ccu CLK_RTC_SPI>;
			clock-names = "r-ahb-rtc", "rtc-1k", "rtc-spi";
			resets = <&r_ccu RST_BUS_RTC>;
			gpr_cur_pos = <6>;
			gpr_bootcount_pos = <7>;
		};

		ir_tx: ir_tx@2800000 {
			compatible = "allwinner,irtx";
			reg = <0x0 0x02800000 0x0 0x400>;
			interrupts = <GIC_SPI 30 IRQ_TYPE_LEVEL_HIGH>;
			clocks = <&ccu CLK_BUS_IR_TX_APB>, <&dcxo24M>, <&ccu CLK_IR_TX>;
			clock-names = "bus", "pclk", "mclk";
			resets = <&ccu RST_BUS_IR_TX>;
			status = "disabled";
		};

		ir_rx: ir_rx@2808000 {
			compatible = "allwinner,irrx";
			reg = <0x0 0x02808000 0x0 0x400>;
			interrupts = <GIC_SPI 31 IRQ_TYPE_LEVEL_HIGH>;
			clocks = <&ccu CLK_BUS_IR_RX0_APB>, <&dcxo24M>, <&ccu CLK_IR_RX0>;
			clock-names = "bus", "pclk", "mclk";
			resets = <&ccu RST_BUS_IR_RX0>;
			status = "disabled";
		};

		s_ir_rx: s_ir_rx@70a8000 {
			compatible = "allwinner,irrx";
			reg = <0x0 0x070a8000 0x0 0x400>;
			interrupts = <GIC_SPI 242 IRQ_TYPE_LEVEL_HIGH>;
			clocks = <&r_ccu CLK_BUS_R_IR_RX>, <&dcxo24M>, <&r_ccu CLK_R_IR_RX>;
			clock-names = "bus", "pclk", "mclk";
			resets = <&r_ccu RST_BUS_R_IR_RX>;
			status = "disabled";
		};

		s_twi0: s_twi0@7108000 {
			#address-cells = <1>;
			#size-cells = <0>;
			compatible = "allwinner,sunxi-twi-v103";
			device_type = "s_twi0";
			reg = <0x0 0x07108000 0x0 0x400>;
			interrupts = <GIC_SPI 239 IRQ_TYPE_LEVEL_HIGH>;
			clocks = <&r_ccu CLK_BUS_R_TWI0>, <&r_ccu CLK_R_APB1>;
			clock-names = "bus", "apb";
			resets = <&r_ccu RST_BUS_R_TWI0>;
			dmas = <&dma 56>, <&dma 56>;
			dma-names = "tx", "rx";
			twi_dvfs_enable;
			status = "disabled";
		};

		s_twi1: s_twi1@7109000 {
			#address-cells = <1>;
			#size-cells = <0>;
			compatible = "allwinner,sunxi-twi-v102";
			device_type = "s_twi1";
			reg = <0x0 0x07109000 0x0 0x400>;
			interrupts = <GIC_SPI 240 IRQ_TYPE_LEVEL_HIGH>;
			clocks = <&r_ccu CLK_BUS_R_TWI1>, <&r_ccu CLK_R_APB1>;
			clock-names = "bus", "apb";
			resets = <&r_ccu RST_BUS_R_TWI1>;
			dmas = <&dma 57>, <&dma 57>;
			dma-names = "tx", "rx";
			status = "disabled";
		};

		s_twi2: s_twi2@710a000 {
			#address-cells = <1>;
			#size-cells = <0>;
			compatible = "allwinner,sunxi-twi-v102";
			device_type = "s_twi2";
			reg = <0x0 0x0710a000 0x0 0x400>;
			interrupts = <GIC_SPI 241 IRQ_TYPE_LEVEL_HIGH>;
			clocks = <&r_ccu CLK_BUS_R_TWI2>, <&r_ccu CLK_R_APB1>;
			clock-names = "bus", "apb";
			resets = <&r_ccu RST_BUS_R_TWI2>;
			dmas = <&dma 58>, <&dma 58>;
			dma-names = "tx", "rx";
			status = "disabled";
		};

		twi0: twi0@2a00000 {
			#address-cells = <1>;
			#size-cells = <0>;
			compatible = "allwinner,sunxi-twi-v102";
			device_type = "twi0";
			reg = <0x0 0x02a00000 0x0 0x400>;
			interrupts = <GIC_SPI 10 IRQ_TYPE_LEVEL_HIGH>;
			clocks = <&ccu CLK_BUS_TWI0_APB>, <&ccu CLK_APB1>;
			clock-names = "bus", "apb";
			resets = <&ccu RST_BUS_TWI0>;
			dmas = <&dma 14>, <&dma 14>;
			dma-names = "tx", "rx";
			status = "disabled";
		};

		twi1: twi1@2a01000 {
			#address-cells = <1>;
			#size-cells = <0>;
			compatible = "allwinner,sunxi-twi-v102";
			device_type = "twi1";
			reg = <0x0 0x02a01000 0x0 0x400>;
			interrupts = <GIC_SPI 11 IRQ_TYPE_LEVEL_HIGH>;
			clocks = <&ccu CLK_BUS_TWI1_APB>, <&ccu CLK_APB1>;
			clock-names = "bus", "apb";
			resets = <&ccu RST_BUS_TWI1>;
			dmas = <&dma 15>, <&dma 15>;
			dma-names = "tx", "rx";
			status = "disabled";
		};

		twi2: twi2@2a02000 {
			#address-cells = <1>;
			#size-cells = <0>;
			compatible = "allwinner,sunxi-twi-v102";
			device_type = "twi2";
			reg = <0x0 0x02a02000 0x0 0x400>;
			interrupts = <GIC_SPI 12 IRQ_TYPE_LEVEL_HIGH>;
			clocks = <&ccu CLK_BUS_TWI2_APB>, <&ccu CLK_APB1>;
			clock-names = "bus", "apb";
			resets = <&ccu RST_BUS_TWI2>;
			dmas = <&dma 16>, <&dma 16>;
			dma-names = "tx", "rx";
			status = "disabled";
		};

		twi3: twi3@2a03000 {
			#address-cells = <1>;
			#size-cells = <0>;
			compatible = "allwinner,sunxi-twi-v102";
			device_type = "twi3";
			reg = <0x0 0x02a03000 0x0 0x400>;
			interrupts = <GIC_SPI 13 IRQ_TYPE_LEVEL_HIGH>;
			clocks = <&ccu CLK_BUS_TWI3_APB>, <&ccu CLK_APB1>;
			clock-names = "bus", "apb";
			resets = <&ccu RST_BUS_TWI3>;
			dmas = <&dma 17>, <&dma 17>;
			dma-names = "tx", "rx";
			status = "disabled";
		};

		twi4: twi4@2a04000 {
			#address-cells = <1>;
			#size-cells = <0>;
			compatible = "allwinner,sunxi-twi-v102";
			device_type = "twi4";
			reg = <0x0 0x02a04000 0x0 0x400>;
			interrupts = <GIC_SPI 14 IRQ_TYPE_LEVEL_HIGH>;
			clocks = <&ccu CLK_BUS_TWI4_APB>, <&ccu CLK_APB1>;
			clock-names = "bus", "apb";
			resets = <&ccu RST_BUS_TWI4>;
			dmas = <&dma 18>, <&dma 18>;
			dma-names = "tx", "rx";
			status = "disabled";
		};

		twi5: twi5@2a05000{
			#address-cells = <1>;
			#size-cells = <0>;
			compatible = "allwinner,sunxi-twi-v102";
			device_type = "twi5";
			reg = <0x0 0x02a05000 0x0 0x400>;
			interrupts = <GIC_SPI 15 IRQ_TYPE_LEVEL_HIGH>;
			clocks = <&ccu CLK_BUS_TWI5_APB>, <&ccu CLK_APB1>;
			clock-names = "bus", "apb";
			resets = <&ccu RST_BUS_TWI5>;
			dmas = <&dma 19>, <&dma 19>;
			dma-names = "tx", "rx";
			status = "disabled";
		};

		pwm0: pwm0@2810000 {
			#pwm-cells = <0x3>;
			compatible = "allwinner,sunxi-pwm-v203";
			reg = <0x0 0x02810000 0x0 0x400>;
			clocks = <&ccu CLK_BUS_PWM0_APB>;
			interrupts = <GIC_SPI 26 IRQ_TYPE_LEVEL_HIGH>;
			resets = <&ccu RST_BUS_PWM0>;
			pwm-number = <4>;
			pwm-base = <0x0>;
			sunxi-pwms = <&pwm0_0>, <&pwm0_1>, <&pwm0_2>, <&pwm0_3>;
			status = "okay";
		};

		pwm0_0: pwm0@2810010 {
			compatible = "allwinner,sunxi-pwm0";
			pinctrl-names = "active", "sleep";
			reg = <0x0 0x02810010 0x0 0x4>;
			reg_base = <0x02810000>;
			status = "disabled";
		};

		pwm0_1: pwm0@2810011 {
			compatible = "allwinner,sunxi-pwm1";
			pinctrl-names = "active", "sleep";
			reg = <0x0 0x02810011 0x0 0x4>;
			reg_base = <0x02810000>;
			status = "disabled";
		};

		pwm0_2: pwm0@2810012 {
			compatible = "allwinner,sunxi-pwm2";
			pinctrl-names = "active", "sleep";
			reg = <0x0 0x02810012 0x0 0x4>;
			reg_base = <0x02810000>;
			status = "disabled";
		};

		pwm0_3: pwm0@2810013 {
			compatible = "allwinner,sunxi-pwm3";
			pinctrl-names = "active", "sleep";
			reg = <0x0 0x02810013 0x0 0x4>;
			reg_base = <0x02810000>;
			status = "disabled";
		};

		s_pwm0: pwm@70a0000 {
			#pwm-cells = <0x3>;
			compatible = "allwinner,sunxi-pwm-v204";
			reg = <0x0 0x070a0000 0x0 0x400>;
			clocks = <&r_ccu CLK_R_PWM>,<&r_ccu CLK_BUS_R_PWM>;
			interrupts = <GIC_SPI 243 IRQ_TYPE_LEVEL_HIGH>;
			clock-names = "clk_pwm","clk_bus_pwm";
			resets = <&r_ccu RST_BUS_R_PWM>;
			pwm-number = <4>;
			pwm-base = <0x4>;
			sunxi-pwms = <&s_pwm0_0>, <&s_pwm0_1>, <&s_pwm0_2>, <&s_pwm0_3>;
			status = "okay";
		};

		s_pwm0_0: s_pwm0@70a0010 {
			compatible = "allwinner,sunxi-pwm4";
			pinctrl-names = "active", "sleep";
			reg = <0x0 0x070a0010 0x0 0x4>;
			reg_base = <0x070a0000>;
			status = "disabled";
		};

		s_pwm0_1: s_pwm0@70a0011 {
			compatible = "allwinner,sunxi-pwm5";
			pinctrl-names = "active", "sleep";
			reg = <0x0 0x070a0011 0x0 0x4>;
			reg_base = <0x070a0000>;
			status = "disabled";
		};

		s_pwm0_2: s_pwm0@70a0012 {
			compatible = "allwinner,sunxi-pwm6";
			pinctrl-names = "active", "sleep";
			reg = <0x0 0x070a0012 0x0 0x4>;
			reg_base = <0x070a0000>;
			status = "disabled";
		};

		s_pwm0_3: s_pwm0@70a0013 {
			compatible = "allwinner,sunxi-pwm7";
			pinctrl-names = "active", "sleep";
			reg = <0x0 0x070a0013 0x0 0x4>;
			reg_base = <0x070a0000>;
			status = "disabled";
		};

		dma: dma-controller@3228000 {
			compatible = "allwinner,dma-v111";
			reg = <0x0 0x3228000 0x0 0x2000>;
			interrupts = <GIC_SPI 100 IRQ_TYPE_LEVEL_HIGH>;
			clocks = <&ccu CLK_BUS_DMA0_AHB>, <&ccu CLK_MBUS_DMA0>, <&ccu CLK_DMA0_MBUS_GATE>;
			clock-names = "bus", "mbus", "mbus-en";
			dma-channels = <8>;
			dma-requests = <64>;
			resets = <&ccu RST_BUS_DMA0>;
			#dma-cells = <1>;
		};

		arm_pmu {
			compatible = "arm,armv8-pmuv3";
			interrupts = <GIC_SPI 316 IRQ_TYPE_LEVEL_HIGH>,
				     <GIC_SPI 317 IRQ_TYPE_LEVEL_HIGH>,
				     <GIC_SPI 318 IRQ_TYPE_LEVEL_HIGH>,
				     <GIC_SPI 319 IRQ_TYPE_LEVEL_HIGH>,
				     <GIC_SPI 348 IRQ_TYPE_LEVEL_HIGH>,
				     <GIC_SPI 349 IRQ_TYPE_LEVEL_HIGH>,
				     <GIC_SPI 374 IRQ_TYPE_LEVEL_HIGH>,
				     <GIC_SPI 375 IRQ_TYPE_LEVEL_HIGH>;
			interrupt-affinity = <&cpu0>, <&cpu1>, <&cpu2>, <&cpu3>, <&cpu4>, <&cpu5>, <&cpu6>, <&cpu7>;
		};

		dump_reg:dump_reg@44000 {
			compatible = "allwinner,sunxi-dump-reg";
			reg = <0x0 0x00044000 0x0 0x0004>;
			ddr-range = <8>;
		};

		hwspinlock: hwspinlock@3220000 {
			compatible = "allwinner,sunxi-hwspinlock";
			reg = <0x0 0x3220000 0x0 0x1000>;
			#hwlock-cells = <1>;
			clocks = <&ccu CLK_BUS_SPINLOCK_AHB>;
			clock-names = "clk_hwspinlock_bus";
			resets = <&ccu RST_BUS_SPINLOCK>;
			reset-names = "rst";
			num-locks = <32>;
			status = "okay";
		};

		sid: sid@3408000 {
			compatible = "allwinner,sunxi-sid";
			reg = <0x0 0x03408000 0x0 0x200>;
			#address-cells = <1>;
			#size-cells = <1>;
			non-secure-maxoffset = <0x50>;
			non-secure-maxlen = <0x10>;

			secure_status {
				offset = <0xa0>;
				size = <0x4>;
			};
			chipid {
				offset = <0x200>;
				size = <0x10>;
			};
			rotpk {
				offset = <0x140>;
				size = <0x20>;
			};

			dvfs_ori {
				offset = <0x214>;
				shift = <16>;
				mask = <0xff>;
			};

			dvfs_bak {
				offset = <0x214>;
				shift = <24>;
				mask = <0xff>;
			};

			res0 {
				offset = <0x240>;
				shift = <24>;
				mask = <0xf>;
			};

			res1 {
				offset = <0x240>;
				shift = <28>;
				mask = <0xf>;
			};
		};

		sram_ctrl: sram_ctrl@3200000 {
			compatible = "allwinner,sram_ctrl";
			reg = <0x0 0x03200000 0 0x184>;
			soc_ver {
				offset = <0x24>;
				mask = <0x7>;
				shift = <0>;
			};
		};

		ths: ths@2818000 {
			compatible = "allwinner,sun65iw1p1-ths";
			reg = <0x0 0x02818000 0x0 0x400>;
			clocks = <&ccu CLK_BUS_TSENSOR_APB>,<&ccu CLK_GPADC0>;
			clock-names = "bus","gpadc";
			resets = <&ccu RST_BUS_TSENSO>;
			#thermal-sensor-cells = <1>;
		};

		sdc2: sdmmc@400A000 {
			compatible = "allwinner,sunxi-mmc-v4p6x";
			device_type = "sdc2";
			reg = <0x0 0x0400A000 0x0 0x1000>;
			interrupts = <GIC_SPI 82 IRQ_TYPE_LEVEL_HIGH>;
			clocks = <&dcxo24M>,
				<&ccu CLK_PLL_PERI1_800M>,
				<&ccu CLK_PLL_PERI1_600M>,
				<&ccu CLK_SMHC2>,
				<&ccu CLK_BUS_SMHC2_AHB>,
				<&ccu CLK_BUS_SMHC2_AHB_SW>;
			clock-names = "osc24m","pll_periph","pll_periph_2","mmc","ahb","mmc_store";
			resets = <&ccu RST_BUS_SMHC2>;
			reset-names = "rst";
			pinctrl-names = "default","sleep";
			pinctrl-0 = <&sdc2_pins_a &sdc2_pins_c &sdc2_pins_d>;
			pinctrl-1 = <&sdc2_pins_b>;
			bus-width = <8>;
			req-page-count = <2>;
			cap-mmc-highspeed;
			cap-cmd23;
			mmc-cache-ctrl;
			non-removable;
			/*max-frequency = <200000000>;*/
			max-frequency = <50000000>;
			cap-erase;
			mmc-high-capacity-erase-size;
			no-sdio;
			no-sd;
			/*-- speed mode --*/
			/*sm0: DS26_SDR12*/
			/*sm1: HSSDR52_SDR25*/
			/*sm2: HSDDR52_DDR50*/
			/*sm3: HS200_SDR104*/
			/*sm4: HS400*/
			/*-- frequency point --*/
			/*f0: CLK_400K*/
			/*f1: CLK_25M*/
			/*f2: CLK_50M*/
			/*f3: CLK_100M*/
			/*f4: CLK_150M*/
			/*f5: CLK_200M*/
			ctl-spec-caps = <0x328>;
			sdc_tm4_sm0_freq0 = <0>;
			sdc_tm4_sm0_freq1 = <0>;
			sdc_tm4_sm1_freq0 = <0x00000000>;
			sdc_tm4_sm1_freq1 = <0>;
			sdc_tm4_sm2_freq0 = <0x00000000>;
			sdc_tm4_sm2_freq1 = <0>;
			sdc_tm4_sm3_freq0 = <0x05000000>;
			sdc_tm4_sm3_freq1 = <0x00000005>;
			sdc_tm4_sm4_freq0 = <0x00050000>;
			sdc_tm4_sm4_freq1 = <0x00000004>;
			sdc_tm4_sm4_freq0_cmd = <0>;
			sdc_tm4_sm4_freq1_cmd = <0>;

			/*vmmc-supply = <&reg_3p3v>;*/
			/*vqmc-supply = <&reg_3p3v>;*/
			/*vdmc-supply = <&reg_3p3v>;*/
			/*vmmc = "vcc-card";*/
			/*vqmc = "";*/
			/*vdmc = "";*/
			/*sunxi-power-save-mode;*/
			status = "disabled";
		};

		sdc0: sdmmc@4008000 {
			compatible = "allwinner,sunxi-mmc-v5p3x";
			device_type = "sdc0";
			reg = <0x0 0x04008000 0x0 0x1000>;
			interrupts = <GIC_SPI 80 IRQ_TYPE_LEVEL_HIGH>;
			clocks = <&dcxo24M>,
				<&ccu CLK_PLL_PERI1_400M>,
				<&ccu CLK_PLL_PERI1_300M>,
				<&ccu CLK_SMHC0>,
				<&ccu CLK_BUS_SMHC0_AHB>,
				<&ccu CLK_BUS_SMHC0_AHB_SW>;
			clock-names = "osc24m","pll_periph","pll_periph_2","mmc","ahb","mmc_store";
			resets = <&ccu RST_BUS_SMHC0>;
			reset-names = "rst";
			pinctrl-names = "default","mmc_1v8","sleep","uart_jtag";
			pinctrl-0 = <&sdc0_pins_a &sdc0_pins_f>;
			pinctrl-1 = <&sdc0_pins_b &sdc0_pins_g>;
			pinctrl-2 = <&sdc0_pins_c>;
			pinctrl-3 = <&sdc0_pins_d &sdc0_pins_e>;
			max-frequency = <50000000>;
			bus-width = <4>;
			req-page-count = <2>;
			/*non-removable;*/
			/*broken-cd;*/
			/*cd-inverted*/
			/*cd-gpios = <&pio PF 6 GPIO_ACTIVE_LOW>;*/
			/* vmmc-supply = <&reg_3p3v>;*/
			/* vqmc-supply = <&reg_3p3v>;*/
			/* vdmc-supply = <&reg_3p3v>;*/
			/*vmmc = "vcc-card";*/
			/*vqmc = "";*/
			/*vdmc = "";*/
			cap-sd-highspeed;
			cap-wait-while-busy;
			/*sd-uhs-sdr50;*/
			/*sd-uhs-ddr50;*/
			/*cap-sdio-irq;*/
			/*keep-power-in-suspend;*/
			/*ignore-pm-notify;*/
			/*sunxi-power-save-mode;*/
			/*sunxi-dly-400k = <1 0 0 0>; */
			/*sunxi-dly-26M  = <1 0 0 0>;*/
			/*sunxi-dly-52M  = <1 0 0 0>;*/
			/*sunxi-dly-52M-ddr4  = <1 0 0 0>;*/
			/*sunxi-dly-52M-ddr8  = <1 0 0 0>;*/
			/*sunxi-dly-104M  = <1 0 0 0>;*/
			/*sunxi-dly-208M  = <1 0 0 0>;*/
			/*sunxi-dly-104M-ddr  = <1 0 0 0>;*/
			/*sunxi-dly-208M-ddr  = <1 0 0 0>;*/
			ctl-spec-caps = <0x408>;
			status = "disabled";
		};

		sdc1: sdmmc@4009000 {
			compatible = "allwinner,sunxi-mmc-v5p3x";
			device_type = "sdc1";
			reg = <0x0 0x04009000 0x0 0x1000>;
			interrupts = <GIC_SPI 81 IRQ_TYPE_LEVEL_HIGH>;
			clocks = <&dcxo24M>,
				 <&ccu CLK_PLL_PERI1_400M>,
				 <&ccu CLK_PLL_PERI1_300M>,
				 <&ccu CLK_SMHC1>,
				 <&ccu CLK_BUS_SMHC1_AHB>,
				 <&ccu CLK_BUS_SMHC1_AHB_SW>;
			clock-names = "osc24m","pll_periph","pll_periph_2","mmc","ahb","mmc_store";
			resets = <&ccu RST_BUS_SMHC1>;
			reset-names = "rst";
			pinctrl-names = "default","sleep";
			pinctrl-0 = <&sdc1_pins_a &sdc1_pins_c>;
			pinctrl-1 = <&sdc1_pins_b>;
			max-frequency = <50000000>;
			bus-width = <4>;
			/*broken-cd;*/
			/*cd-inverted*/
			/*cd-gpios = <&pio PG 6 6 1 2 0>;*/
			/* vmmc-supply = <&reg_3p3v>;*/
			/* vqmc-supply = <&reg_3p3v>;*/
			/* vdmc-supply = <&reg_3p3v>;*/
			/*vmmc = "vcc-card";*/
			/*vqmc = "";*/
			/*vdmc = "";*/
			cap-sd-highspeed;
			cap-sdio-irq;
			ignore-pm-notify;
			/*sd-uhs-sdr50;*/
			/*sd-uhs-ddr50;*/
			/*sd-uhs-sdr104;*/
			/*cap-sdio-irq;*/
			keep-power-in-suspend;
			execute_tuning_in_kernel;
			/*ignore-pm-notify;*/
			/*sunxi-power-save-mode;*/
			/*sunxi-dly-400k = <0xff 0xff 0xff 0xff 0xff 0xff>; */
			/*sunxi-dly-26M  = <0xff 0xff 0xff 0xff 0xff 0xff>;*/
			/*sunxi-dly-52M  = <0xff 0xff 0xff 0xff 0xff 0xff>;*/
			/*sunxi-dly-52M-ddr4  = <0xff 0xff 0xff 0xff 0xff 0xff>;*/
			/*sunxi-dly-52M-ddr8  = <0xff 0xff 0xff 0xff 0xff 0xff>;*/
			/*sunxi-dly-104M  = <0xff 0xff 0xff 0xff 0xff 0xff>;*/
			/*sunxi-dly-208M  = <0xff 0xff 0xff 0xff 0xff 0xff> ;*/
			/*sunxi-dly-104M-ddr  = <0xff 0xff 0xff 0xff 0xff 0xff>;*/
			/*sunxi-dly-208M-ddr  = <0xff 0xff 0xff 0xff 0xff 0xff>;*/
			sunxi-dly-208M  = <0xff 0x1 0xff 0xff 0xff 0xff>;
			ctl-spec-caps = <0x428>;
			status = "disabled";
		};

		wdt: watchdog@3010000 {
			compatible = "allwinner,wdt-v103";
			reg = <0x0 0x03010000 0x0 0x20>;
			interrupts = <GIC_SPI 106 IRQ_TYPE_LEVEL_HIGH>;  /* In GIC Spec */
			sys-24m-clk-select = <1>;
		};

		/*
		 * channel0~3  : cpux -> e902
		 */
		msgbox: msgbox@3210000 {
			compatible = "allwinner,sun65iw1-msgbox";
			#mbox-cells = <1>;
			reg = <0x0 0x03210000 0x0 0x1000>,
			      <0x0 0x03211000 0x0 0x1000>;
			interrupts = <GIC_SPI 0 IRQ_TYPE_LEVEL_HIGH>,
					<GIC_SPI 1 IRQ_TYPE_LEVEL_HIGH>;
			clocks = <&ccu CLK_BUS_MSGBOX_CPUX_AHB>;
			clock-names = "msgbox";
			resets = <&ccu RST_BUS_MSGBOX_CPUX>;
			reset-names = "rst";
			local_id = <0>;
			status = "okay";
		};

		spi0: spi@2c00000 {
			#address-cells = <1>;
			#size-cells = <0>;
			compatible = "allwinner,sunxi-spi-v1.3";
			reg = <0x0 0x02c00000 0x0 0x1000>;
			interrupts = <GIC_SPI 18 IRQ_TYPE_LEVEL_HIGH>;
			clocks = <&ccu CLK_PLL_PERI0_300M>, <&ccu CLK_SPI0>, <&ccu CLK_BUS_SPI0_AHB>;
			clock-names = "pll", "mod", "bus";
			resets = <&ccu RST_BUS_SPI0>;
			dmas = <&dma 22>, <&dma 22>;
			dma-names = "tx", "rx";
			clock-frequency = <100000000>;
			sunxi,spi-num-cs = <2>;
			status = "disabled";
		};

		spi1: spi@2c01000 {
			#address-cells = <1>;
			#size-cells = <0>;
			compatible = "allwinner,sunxi-spi-v1.4";
			reg = <0x0 0x02c01000 0x0 0x1000>;
			interrupts = <GIC_SPI 19 IRQ_TYPE_LEVEL_HIGH>;
			clocks = <&ccu CLK_PLL_PERI0_300M>, <&ccu CLK_SPI1>, <&ccu CLK_BUS_SPI1_AHB>;
			clock-names = "pll", "mod", "bus";
			resets = <&ccu RST_BUS_SPI1>;
			dmas = <&dma 23>, <&dma 23>;
			dma-names = "tx", "rx";
			clock-frequency = <100000000>;
			sunxi,spi-num-cs = <1>;
			status = "disabled";
		};

		spi2: spi@2c02000 {
			#address-cells = <1>;
			#size-cells = <0>;
			compatible = "allwinner,sunxi-spi-v1.3";
			reg = <0x0 0x02c02000 0x0 0x1000>;
			interrupts = <GIC_SPI 20 IRQ_TYPE_LEVEL_HIGH>;
			clocks = <&ccu CLK_PLL_PERI0_300M>, <&ccu CLK_SPI2>, <&ccu CLK_BUS_SPI2_AHB>;
			clock-names = "pll", "mod", "bus";
			resets = <&ccu RST_BUS_SPI2>;
			dmas = <&dma 24>, <&dma 24>;
			dma-names = "tx", "rx";
			clock-frequency = <100000000>;
			sunxi,spi-num-cs = <1>;
			status = "disabled";
		};

		r_spi0: spi@7280000 {
			#address-cells = <1>;
			#size-cells = <0>;
			compatible = "allwinner,sunxi-spi-v1.3";
			reg = <0x0 0x07280000 0x0 0x1000>;
			interrupts = <GIC_SPI 246 IRQ_TYPE_LEVEL_HIGH>;
			clocks = <&ccu CLK_PLL_PERI0_300M>, <&r_ccu CLK_R_SPI>, <&r_ccu CLK_BUS_R_SPI>;
			clock-names = "pll", "mod", "bus";
			resets = <&r_ccu RST_BUS_R_SPI>;
			dmas = <&dma 62>, <&dma 62>;
			dma-names = "tx", "rx";
			clock-frequency = <100000000>;
			sunxi,spi-num-cs = <1>;
			status = "disabled";
		};

		gpu:gpu@1800000 {
			device_type = "gpu";
			compatible = "arm,mali-valhall";
			reg = <0x0 0x01800000 0x0 0x10000>;
			interrupts = <GIC_SPI 179 IRQ_TYPE_LEVEL_HIGH>,
				     <GIC_SPI 180 IRQ_TYPE_LEVEL_HIGH>,
				     <GIC_SPI 181 IRQ_TYPE_LEVEL_HIGH>;
			interrupt-names = "JOB", "MMU", "GPU";
			clocks = <&ccu CLK_GPU>,
				<&ccu CLK_BUS_GPU_AHB>,
				<&ccu CLK_PLL_GPU>,
				<&ccu CLK_BUS_GPU_AHB_SW>,
				<&ccu CLK_BUS_GPU_AXI>,
				<&ccu CLK_PLL_PERI0_800M>,
				<&ccu CLK_PLL_PERI0_600M>,
				<&ccu CLK_PLL_PERI0_400M>,
				<&ccu CLK_PLL_PERI0_300M>,
				<&ccu CLK_PLL_PERI0_200M>;
			clock-names = "clk_mali", "clk_bus", "clk_parent", "gpu-ahb-gate",
				"gpu-axi-gate", "clk_800", "clk_600", "clk_400", "clk_300",
				"clk_200";
			resets = <&ccu RST_BUS_GPU>, <&ccu RST_BUS_GPU_AXIMON>;
			reset-names = "rst_bus_gpu", "rst_bus_gpu_axi";
			operating-points-v2 = <&gpu_opp_table>;
			#cooling-cells = <2>;
			ipa_dvfs:ipa_dvfs {
				compatible = "arm,mali-simple-power-model";
				static-coefficient = <636>;
				dynamic-coefficient = <1434>;
				/* ts0 -> ts3 */
				ts = <0xcc77c0 217000 0xffffd508 200>;
				thermal-zone = "gpu_thermal_zone";
				/*ss-coefficient = <36>;*/
				/*ff-coefficient = <291>;*/
			};
			/*power-domains = <&pd1 A523_PCK_GPU>;*/
		};

		sunxi_drm: sunxi-drm {
			compatible = "allwinner,sunxi-drm";
			fb_base = <0>;
			status = "okay";
		};

		de: de@5000000 {
			compatible = "allwinner,display-engine-v355";
			iommus = <&mmu_aw 5 1>;
			reg = <0x0 0x5000000 0x0 0x400000>;
			interrupts = <GIC_SPI 146 IRQ_TYPE_LEVEL_HIGH>;
			clocks = <&ccu CLK_DE>,
				 <&ccu CLK_BUS_DE0_AHB>,
				 <&ccu CLK_MBUS_DE_SYS>;
			clock-names = "clk_de",
				      "clk_ahb_de",
				      "clk_bus_de";
			resets = <&ccu RST_BUS_DE0>;
			reset-names = "rst_bus_de";
			assigned-clocks = <&ccu CLK_DE>;
			assigned-clock-parents = <&ccu CLK_PLL_PERI0_480M>;
			assigned-clock-rates = <480000000>;
			power-domains = <&pd SUN65IW1_PCK_VO>;
			sys = <&vo0>;
			status = "disabled";
			operating-points-v2 = <&de_opp_table>;
			ports {
				#address-cells = <1>;
				#size-cells = <0>;
				disp0: port@0 {
					reg = <0>;
					#address-cells = <1>;
					#size-cells = <0>;
					disp0_out_tcon0: endpoint@0 {
						reg = <0>;
						remote-endpoint = <&tcon0_in_disp0>;
					};
					disp0_out_tcon4: endpoint@3 {
						reg = <4>;
						remote-endpoint = <&tcon4_in_disp0>;
					};
				};
				disp1: port@1 {
					reg = <1>;
					#address-cells = <1>;
					#size-cells = <0>;
					disp1_out_tcon0: endpoint@0 {
						reg = <0>;
						remote-endpoint = <&tcon0_in_disp1>;
					};
					disp1_out_tcon4: endpoint@3 {
						reg = <4>;
						remote-endpoint = <&tcon4_in_disp1>;
					};
				};
			};
		};

		vo0: vo0@5a00000 {
			compatible = "allwinner,tcon-top0";
			reg = <0x0 0x05a00000 0x0 0xfff>;
			clocks = <&ccu CLK_BUS_VO0_AHB>,
				 <&ccu CLK_BUS_VIDEO_OUT0_AHB_SW>;
			clock-names = "clk_ahb",
				      "clk_ahb_gate";
			resets = <&ccu RST_BUS_VIDEO_OUT0>,
				 <&ccu RST_BUS_VO0>;
			reset-names = "rst_bus_dpss_top",
				       "rst_bus_reg";
			power-domains = <&pd SUN65IW1_PCK_VO>;
			status = "disabled";
		};

		dlcd0: tcon0@5a08000 {
			compatible = "allwinner,tcon-lcd";
			reg = <0x0 0x05a08000 0x0 0x1000>;
			interrupts = <GIC_SPI 154 IRQ_TYPE_LEVEL_HIGH>;

			clocks = <&ccu CLK_BUS_TCON_LCD0_AHB>;
			clock-names = "clk_bus_tcon";
			resets = <&ccu RST_BUS_TCON_LCD0>;
			reset-names = "rst_bus_tcon";
			top = <&vo0>;
			status = "disabled";
			ports {
				#address-cells = <1>;
				#size-cells = <0>;
				tcon0_in: port@0 {
					#address-cells = <1>;
					#size-cells = <0>;
					reg = <0>;
					tcon0_in_disp0: endpoint@0 {
						reg = <0>;
						remote-endpoint = <&disp0_out_tcon0>;
					};
					tcon0_in_disp1: endpoint@1 {
						reg = <1>;
						remote-endpoint = <&disp1_out_tcon0>;
					};
				};
				tcon_out: port@1 {
					#address-cells = <1>;
					#size-cells = <0>;
					reg = <1>;
					tcon0_out_dsi0: endpoint@0 {
						reg = <0>;
						remote-endpoint = <&dsi0_in_tcon0>;
					};
					tcon0_out_lvds0: endpoint@1 {
						reg = <1>;
						remote-endpoint = <&lvds0_in_tcon0>;
					};
					tcon0_out_rgb0: endpoint@2 {
						reg = <2>;
						remote-endpoint = <&rgb0_in_tcon0>;
					};
				};
			};
		};

		dsi0combophy: phy@5a11000 {
			compatible = "allwinner,sunxi-dsi-combo-phy0,sun65iw1";
			reg = <0x0 0x05a11000 0x0 0xfff>;
			clocks = <&ccu CLK_BUS_MIPI_DSI0_AHB>;
			clock-names = "phy_gating_clk";
			resets = <&ccu RST_BUS_MIPI_DSI0>;
			reset-names = "phy_rst_clk";
			#clock-cells = <1>;
			#phy-cells = <0>;
			status = "disabled";
		};

		dsi0: dsi0@5a10000 {
			compatible = "allwinner,dsi0";
			reg = <0x0 0x05a10000 0x0 0xfff>;
			interrupts = <GIC_SPI 158 IRQ_TYPE_LEVEL_HIGH>;
			clocks = <&ccu CLK_MIPI_DSI0>,
				<&ccu CLK_BUS_MIPI_DSI0_AHB>,
				<&dsi0combophy CLK_DSI_HS>,
				<&dsi0combophy CLK_DSI_LS>;
			clock-names = "dsi_clk",
					"dsi_gating_clk",
					"displl_hs",
					"displl_ls";
			resets = <&ccu RST_BUS_MIPI_DSI0>;
			reset-names = "dsi_rst_clk";
			phys = <&dsi0combophy>;
			phy-names = "combophy";
			status = "disabled";

			ports {
				#address-cells = <1>;
				#size-cells = <0>;
				dsi0_in: port@0 {
					#address-cells = <1>;
					#size-cells = <0>;
					reg = <0>;
					dsi0_in_tcon0: endpoint@0 {
						reg = <0>;
						remote-endpoint = <&tcon0_out_dsi0>;
					};
				};
			};
		};

		rgb0: rgb0@1000 {
			compatible = "allwinner,rgb0";
			clocks = <&dsi0combophy CLK_LVDS_OR_RGB>;
			clock-names = "rgb_pclk";
			phys = <&dsi0combophy>;
			phy-names = "combophy0";
			status = "disabled";
			ports {
				#address-cells = <1>;
				#size-cells = <0>;
				rgb0_in: port@0 {
					#address-cells = <1>;
					#size-cells = <0>;
					reg = <0>;
					rgb0_in_tcon0: endpoint@0 {
						reg = <0>;
						remote-endpoint = <&tcon0_out_rgb0>;
					};
				};
			};
		};

		lvds0: lvds0@1000 {
			compatible = "allwinner,lvds0";
			clocks = <&dsi0combophy CLK_LVDS_OR_RGB>;
			clock-names = "lvds_pclk";
			resets = <&ccu RST_BUS_LVDS0>;
			reset-names = "rst_bus_lvds";
			phys = <&dsi0combophy>;
			phy-names = "combophy0";
			status = "disabled";

			ports {
				#address-cells = <1>;
				#size-cells = <0>;
				lvds0_in: port@0 {
					#address-cells = <1>;
					#size-cells = <0>;
					reg = <0>;
					lvds0_in_tcon0: endpoint@0 {
						reg = <0>;
						remote-endpoint = <&tcon0_out_lvds0>;
					};
				};
			};
		};

		vo1: vo1@5c00000 {
			compatible = "allwinner,tcon-top1";
			reg = <0x0 0x05c00000 0x0 0xfff>;
			clocks = <&ccu CLK_BUS_VO1_AHB>,
				 <&ccu CLK_BUS_VIDEO_OUT0_AHB_SW>;
			clock-names = "clk_ahb",
				      "clk_ahb_gate";
			resets = <&ccu RST_BUS_VIDEO_OUT0>,
				<&ccu RST_BUS_VO1>;
			reset-names = "rst_bus_dpss_top",
				      "rst_bus_reg";
			status = "disabled";
		};

		tv0: tcon4@5c08000 {
			compatible = "allwinner,tcon-tv";
			reg = <0x0 0x05c08000 0x0 0x1000>;
			interrupts = <GIC_SPI 156 IRQ_TYPE_LEVEL_HIGH>;
			clocks = <&ccu CLK_TCON_TV0_EDP>,
				<&ccu CLK_BUS_TCON_TV0_AHB>;
			clock-names = "clk_tcon",
					"clk_bus_tcon";
			resets = <&ccu RST_BUS_TCON_TV0>;
			reset-names = "rst_bus_tcon";
			top = <&vo1>;
			status = "disabled";
			ports {
				#address-cells = <1>;
				#size-cells = <0>;
				tcon4_in: port@0 {
					#address-cells = <1>;
					#size-cells = <0>;
					reg = <0>;
					tcon4_in_disp0: endpoint@0 {
						reg = <0>;
						remote-endpoint = <&disp0_out_tcon4>;
					};
					tcon4_in_disp1: endpoint@1 {
						reg = <1>;
						remote-endpoint = <&disp1_out_tcon4>;
					};
				};
				tcon4_out: port@1 {
					#address-cells = <1>;
					#size-cells = <0>;
					reg = <1>;
					tcon4_out_edp0: endpoint@0 {
						reg = <0>;
						remote-endpoint = <&edp0_in_tcon4>;
					};
					tcon4_out_dp0: endpoint@1 {
						reg = <1>;
						remote-endpoint = <&dp0_in_tcon4>;
					};
				};
			};
		};

		edp0: edp0@5c10000 {
			compatible = "allwinner,drm-edp";
			reg = <0x0 0x05c10000 0x0 0x4000>;
			interrupts = <GIC_SPI 160 IRQ_TYPE_LEVEL_HIGH>;
			clocks = <&ccu CLK_BUS_EDP_AHB>,
				<&ccu CLK_TCON_TV0_EDP>;
			clock-names = "clk_bus_edp",
				"clk_edp";
			use_inner_clk = <1>;
			resets = <&ccu RST_BUS_EDP>;
			reset-names = "rst_bus_edp";
			/* assigned-clocks = <&ccu CLK_TCON_TV0_EDP>; */
			/* assigned-clock-parents = <&ccu CLK_PLL_VIDEO1_4X>; */
			power-domains = <&pd SUN65IW1_PCK_VO>;
			sys = <&vo1>;
			status = "disabled";
			ports {
				#address-cells = <1>;
				#size-cells = <0>;
				edp_in: port@0 {
					#address-cells = <1>;
					#size-cells = <0>;
					reg = <0>;
					edp0_in_tcon4: endpoint@0 {
						reg = <0>;
						remote-endpoint = <&tcon4_out_edp0>;
					};
				};
				edp_out: port@1 {
					#address-cells = <1>;
					#size-cells = <0>;
					reg = <1>;
				};
			};
		};

		dp0: dp0@5c10000 {
			compatible = "allwinner,drm-dp";
			reg = <0x0 0x05c10000 0x0 0x4000>;
			interrupts = <GIC_SPI 160 IRQ_TYPE_LEVEL_HIGH>;
			clocks = <&ccu CLK_BUS_EDP_AHB>,
				<&ccu CLK_TCON_TV0_EDP>;
			clock-names = "clk_bus_edp",
				"clk_edp";
			use_inner_clk = <1>;
			resets = <&ccu RST_BUS_EDP>;
			reset-names = "rst_bus_edp";
			/* assigned-clocks = <&ccu CLK_TCON_TV0_EDP>; */
			/* assigned-clock-parents = <&ccu CLK_PLL_VIDEO1_4X>; */
			power-domains = <&pd SUN65IW1_PCK_VO>;
			sys = <&vo1>;
			status = "disabled";
			ports {
				#address-cells = <1>;
				#size-cells = <0>;
				dp_in: port@0 {
					#address-cells = <1>;
					#size-cells = <0>;
					reg = <0>;
					dp0_in_tcon4: endpoint@0 {
						reg = <0>;
						remote-endpoint = <&tcon4_out_dp0>;
					};
				};
				dp_out: port@1 {
					#address-cells = <1>;
					#size-cells = <0>;
					reg = <1>;
				};
			};
		};

		ce0: ce@3412000 {
			compatible = "allwinner,sunxi-ce";
			device_name = "ce";
			reg = <0x0 0x03412000 0x0 0x800>, /* non-secure space */
				<0x0 0x03412800 0x0 0x800>; /* secure space */
			interrupts = <GIC_SPI 96 IRQ_TYPE_EDGE_RISING>, /*non-secure*/
				<GIC_SPI 97 IRQ_TYPE_EDGE_RISING>; /* secure*/
			clock-frequency = <400000000>; /* 400MHz */
			clocks = <&ccu CLK_BUS_CE_SYS_AXIMON>, <&ccu CLK_BUS_CE_SYS_IP_AHB>, <&ccu CLK_BUS_CE_SYS_AXI>,
				<&ccu CLK_PLL_PERI0_400M>, <&ccu CLK_CE_SYS>;
			clock-names = "bus_ce", "ce_clk", "mbus_ce", "clk_src", "ce_sys_clk";
			resets = <&ccu RST_BUS_CE_SYS_AXIMON>, <&ccu RST_BUS_CE_SY>;
			reset-names = "rst_bus_ce", "rst_ce_clk";
			low-power-mode;
			status = "okay";
		};

		gpadc0: gpadc0@2820000 {
			compatible = "allwinner,sunxi-gpadc-v101";
			reg = <0x0 0x02820000 0x0 0x400>;
			interrupts = <GIC_SPI 36 IRQ_TYPE_LEVEL_HIGH>;
			clocks = <&ccu CLK_BUS_GPADC0_APB>, <&ccu CLK_GPADC0>;
			clock-names = "bus", "hosc";
			resets = <&ccu RST_BUS_GPADC0>;
			status = "disabled";
		};

		ledc: ledc@2830000 {
			#address-cells = <1>;
			#size-cells = <0>;
			compatible = "allwinner,sunxi-leds";
			reg = <0x0 0x02830000 0x0 0x400>;
			interrupts = <GIC_SPI 35 IRQ_TYPE_LEVEL_HIGH>;
			clocks = <&ccu CLK_LEDC>, <&ccu CLK_BUS_LEDC_APB>;
			clock-names = "clk_ledc", "clk_cpuapb";
			resets = <&ccu RST_BUS_LEDC>;
			reset-names = "ledc_reset";
			dmas = <&dma 12>;
			dma-names = "tx";
			status = "disabled";
		};

		nsi0: nsi-controller@2400000 {
			compatible = "allwinner,sunxi-nsi-v2";
			interrupts = <GIC_SPI 90 IRQ_TYPE_LEVEL_HIGH>;
			reg = <0x0 0x02400000 0x0 0x10000>,
				  <0x0 0x02410000 0x0 0x400>;
			clocks = <&ccu CLK_PLL_PERI0_600M>, <&ccu CLK_MBUS>,
				<&ccu CLK_NSI>, <&ccu CLK_PLL_PERI0_600M>,
				<&ccu CLK_AHB>, <&drampll_ccu CLK_DFI>;
			clock-names = "pll", "bus", "nsi", "nsi-p","ahb", "cpu_direct";
			resets = <&ccu RST_BUS_NSI>, <&ccu RST_BUS_NSI_CFG>;
			reset-names = "bus_nsi", "bus_nsi_cfg";
			clock-frequency = <600000000>, <600000000>;
			#nsi-cells = <1>;
			clk_path_type = <1>;
			topology_type = <2>;
			channel_type = <1>;
			master_clks = <0 1>, <1 1>, <2 1>, <3 1>, <4 2>, <5 1>, <6 1>, <7 1>,
					<8 1>, <9 2>, <10 1>, <11 1>, <12 2>, <13 4>, <14 4>, <15 4>,
					<16 4>, <17 4>, <18 4>, <22 5>;
			ia_pmu_data_unit = <64>;
			ta_pmu_data_unit = <64>;
			ra_pmu_data_unit = <64>;
			cpu_pmu_data_unit = <64>;
			sub_node_id_mapping;

			cpu{
				id = <19>;
				cpu_direct_reg = <0x02410000 0x010c>;
			};

			iommu{
				id = <6>;
				mode = <0>;
				pri = <3>;
				select = <1>;
			};
			de {
				id = <2>;
				mode = <0>;
				pri = <2>;
				select = <1>;
			};
			eink {
				id = <3>;
				mode = <0>;
				pri = <1>;
				select = <1>;
			};
			g2d {
				id = <7>;
				mode = <0>;
				pri = <1>;
				select = <1>;
			};
			ve {
				id = <5>;
				mode = <0>;
				pri = <1>;
				select = <1>;
			};
			isp {
				id = <0>;
				mode = <0>;
				pri = <2>;
				select = <1>;
			};
			csi {
				id = <1>;
				mode = <0>;
				pri = <2>;
				select = <1>;
			};
			smhc2 {
				id = <18>;
				mode = <0>;
				pri = <2>;
				select = <1>;
			};
		};

		/* audio dirver module -> audio codec */
		codec:codec@2908000 {
			#sound-dai-cells = <0>;
			compatible	= "allwinner,sunxi-snd-codec";
			reg		= <0x0 0x02908000 0x0 0x348>;
			resets		= <&ccu RST_BUS_AUDIOCODEC0>;
			clocks		= <&ccu CLK_BUS_AUDIOCODEC0_APB>,
					  <&ccu CLK_PLL_AUDIO0>,
					  <&ccu CLK_PLL_AUDIO1_2X>,
					  <&ccu CLK_PLL_AUDIO1_5X>,
					  <&ccu CLK_AUDIOCODEC0_DAC>,
					  <&ccu CLK_AUDIOCODEC0_ADC>;
			clock-names	= "clk_bus_adda",
					  "clk_pll_audio0",
					  "clk_pll_audio1_2x",
					  "clk_pll_audio1_5x",
					  "clk_adda_dac",
					  "clk_adda_adc";
			interrupts	= <GIC_SPI 58 IRQ_TYPE_LEVEL_HIGH>;
			status = "disabled";
		};

		codec_plat:codec_plat {
			#sound-dai-cells = <0>;
			compatible	= "allwinner,sunxi-snd-plat-aaudio";
			dac-txdata	= <0x02908020>;
			adc-txdata	= <0x02908040>;
			dmas		= <&dma 7>, <&dma 7>;
			dma-names	= "tx", "rx";
			playback-cma	= <128>;
			capture-cma	= <128>;
			tx-fifo-size	= <128>;
			rx-fifo-size	= <128>;
			dma-buf-mode	= <0>;
			status = "disabled";
		};

		codec_mach:codec_mach {
			compatible = "allwinner,sunxi-snd-mach";
			soundcard-mach,name		= "audiocodec";
			soundcard-mach,pin-switches	= "MIC1", "MIC2",
							  "LINEOUTL", "LINEOUTR",
							  "HPOUT", "SPK";
			soundcard-mach,routing		= "MIC1P_PIN", "MIC1",
							  "MIC1N_PIN", "MIC1",
							  "MIC2P_PIN", "MIC2",
							  "MIC2N_PIN", "MIC2",
							  "LINEOUTL", "LINEOUTLP_PIN",
							  "LINEOUTL", "LINEOUTLN_PIN",
							  "LINEOUTR", "LINEOUTRP_PIN",
							  "LINEOUTR", "LINEOUTRN_PIN",
							  "SPK", "LINEOUTLP_PIN",
							  "SPK", "LINEOUTLN_PIN",
							  "SPK", "LINEOUTRP_PIN",
							  "SPK", "LINEOUTRN_PIN",
							  "HPOUT", "HPOUTL_PIN",
							  "HPOUT", "HPOUTR_PIN";
			soundcard-mach,jack-support = <1>;
			status = "disabled";
			soundcard-mach,cpu {
				sound-dai = <&codec_plat>;
			};
			soundcard-mach,codec {
				sound-dai = <&codec>;
				soundcard-mach,pll-fs	= <1>;
			};
		};

		/* audio dirver module -> external-ac203c */
		ac203c_clocks:ac203c_clocks {
			compatible = "allwinner,sunxi-snd-ac203c-clocks";
			resets		= <&ccu RST_BUS_AUDIOCODEC1>;
			clocks		= <&ccu CLK_BUS_AUDIOCODEC1_APB>,
					  <&ccu CLK_PLL_AUDIO0>,
					  <&ccu CLK_PLL_AUDIO1_2X>,
					  <&ccu CLK_PLL_AUDIO1_5X>,
					  <&ccu CLK_AUDIOCODEC1_DAC>;
			clock-names	= "clk_bus_adda",
					  "clk_pll_audio0",
					  "clk_pll_audio1_2x",
					  "clk_pll_audio1_5x",
					  "clk_adda_dac";
			status		= "okay";
		};

		ac203c_plat:ac203c_plat {
			#sound-dai-cells = <0>;
			compatible	= "allwinner,sunxi-snd-plat-aaudio";
			dac-txdata	= <0x02909020>;
			adc-txdata	= <0x02909618>;
			dmas		= <&dma 9>, <&dma 9>;
			dma-names	= "tx", "rx";
			playback-cma	= <128>;
			capture-cma	= <128>;
			tx-fifo-size	= <128>;
			rx-fifo-size	= <128>;
			dma-buf-mode	= <0>;
			status = "disabled";
		};

		ac203c_mach:ac203c_mach {
			compatible = "allwinner,sunxi-snd-mach";
			soundcard-mach,name		= "audiocodec";
			soundcard-mach,pin-switches	= "MIC1", "MIC2", "MIC3", "MIC4",
							  "HPOUT", "LINEOUTL", "LINEOUTR", "SPK";
			soundcard-mach,routing	= "MIC1P_PIN", "MIC1",
						  "MIC1N_PIN", "MIC1",
						  "MIC2P_PIN", "MIC2",
						  "MIC2N_PIN", "MIC2",
						  "MIC3P_PIN", "MIC3",
						  "MIC3N_PIN", "MIC3",
						  "MIC4P_PIN", "MIC4",
						  "MIC4N_PIN", "MIC4",
						  "LINEOUTL", "LINEOUTLP_PIN",
						  "LINEOUTL", "LINEOUTLN_PIN",
						  "LINEOUTR", "LINEOUTRP_PIN",
						  "LINEOUTR", "LINEOUTRN_PIN",
						  "SPK", "LINEOUTLP_PIN",
						  "SPK", "LINEOUTLN_PIN",
						  "SPK", "LINEOUTRP_PIN",
						  "SPK", "LINEOUTRN_PIN",
						  "HPOUT", "HPOUT_PIN";
			status = "disabled";
			soundcard-mach,cpu {
				sound-dai = <&ac203c_plat>;
			};
			soundcard-mach,codec {
			};
		};

		/* audio dirver module -> hdmi */
		hdmi_codec:hdmi_codec {
			#sound-dai-cells = <0>;
			compatible	= "allwinner,sunxi-snd-codec-hdmi";
			status = "disabled";
		};

		/* audio dirver module -> edp */
		edp_codec:edp_codec {
			#sound-dai-cells = <0>;
			compatible	= "allwinner,sunxi-snd-codec-edp";
			status = "disabled";
		};

		/* audio dirver module -> owa */
		owa_plat:owa_plat@2918000 {
			#sound-dai-cells = <0>;
			compatible	= "allwinner,sunxi-snd-plat-owa";
			reg		= <0x0 0x02918000 0x0 0x5C>;
			resets		= <&ccu RST_BUS_OWA0>;
			clocks		= <&ccu CLK_BUS_OWA0_APB>,
					  <&ccu CLK_PLL_PERI0_300M>,
					  <&ccu CLK_PLL_PERI0_400M>,
					  <&ccu CLK_PLL_AUDIO0>,
					  <&ccu CLK_PLL_AUDIO1_2X>,
					  <&ccu CLK_PLL_AUDIO1_5X>,
					  <&ccu CLK_OWA0_TX>,
					  <&ccu CLK_OWA0_RX>;
			clock-names	= "clk_bus_owa",
					  "clk_pll_peri0_300m",
					  "clk_pll_peri0_400m",
					  "clk_pll_audio0",
					  "clk_pll_audio1_2x",
					  "clk_pll_audio1_5x",
					  "clk_owa_tx",
					  "clk_owa_rx";
			dmas		= <&dma 2>, <&dma 2>;
			dma-names	= "tx", "rx";
			playback-cma	= <128>;
			capture-cma	= <128>;
			tx-fifo-size	= <128>;
			rx-fifo-size	= <128>;
			interrupts	= <GIC_SPI 56 IRQ_TYPE_LEVEL_HIGH>;
			status = "disabled";
		};

		owa_mach:owa_mach {
			compatible = "allwinner,sunxi-snd-mach";
			soundcard-mach,name = "sndowa";
			status = "disabled";
			soundcard-mach,cpu {
				sound-dai = <&owa_plat>;
			};
			soundcard-mach,codec {
			};
		};

		/* audio dirver module -> dmic */
		dmic_plat:dmic_plat@2910000 {
			#sound-dai-cells = <0>;
			compatible	= "allwinner,sunxi-snd-plat-dmic";
			reg		= <0x0 0x02910000 0x0 0x50>;
			resets		= <&ccu RST_BUS_DMIC>;
			clocks		= <&ccu CLK_BUS_DMIC_APB>,
					  <&ccu CLK_PLL_AUDIO0>,
					  <&ccu CLK_PLL_AUDIO1_2X>,
					  <&ccu CLK_PLL_AUDIO1_5X>,
					  <&ccu CLK_DMIC>;
			clock-names	= "clk_bus_dmic",
					  "clk_pll_audio0",
					  "clk_pll_audio1_2x",
					  "clk_pll_audio1_5x",
					  "clk_dmic";
			dmas		= <&dma 8>;
			dma-names	= "rx";
			capture-cma	= <128>;
			rx-fifo-size	= <128>;
			status = "disabled";
		};

		dmic_mach:dmic_mach{
			compatible = "allwinner,sunxi-snd-mach";
			soundcard-mach,name		= "snddmic";
			soundcard-mach,capture-only;
			status = "disabled";
			soundcard-mach,cpu {
				sound-dai = <&dmic_plat>;
			};
			soundcard-mach,codec {
			};
		};

		/* audio dirver module -> I2S/PCM */
		i2s0_plat:i2s0_plat@2900000 {
			#sound-dai-cells = <0>;
			compatible = "allwinner,sunxi-snd-plat-i2s";
			reg		= <0x0 0x02900000 0x0 0x7C>;
			resets		= <&ccu RST_BUS_I2S0>;
			clocks		= <&ccu CLK_BUS_I2S0_APB>,
					  <&ccu CLK_PLL_PERI0_200M>,
					  <&ccu CLK_PLL_AUDIO0>,
					  <&ccu CLK_PLL_AUDIO1_2X>,
					  <&ccu CLK_PLL_AUDIO1_5X>,
					  <&ccu CLK_I2S0>;
			clock-names	= "clk_bus_i2s",
					  "clk_pll_peri0_200m",
					  "clk_pll_audio0",
					  "clk_pll_audio1_2x",
					  "clk_pll_audio1_5x",
					  "clk_i2s";
			dmas		= <&dma 3>, <&dma 3>;
			dma-names	= "tx", "rx";
			playback-cma	= <128>;
			capture-cma	= <128>;
			tx-fifo-size	= <128>;
			rx-fifo-size	= <128>;
			status = "disabled";
		};

		i2s0_mach:i2s0_mach{
			compatible = "allwinner,sunxi-snd-mach";
			soundcard-mach,name		= "sndi2s0";
			soundcard-mach,format		= "i2s";
			soundcard-mach,slot-num		= <2>;
			soundcard-mach,slot-width	= <32>;
			status = "disabled";
			soundcard-mach,cpu {
				sound-dai = <&i2s0_plat>;
			};
			soundcard-mach,codec {
			};
		};

		i2s1_plat:i2s1_plat@2901000 {
			#sound-dai-cells = <0>;
			compatible = "allwinner,sunxi-snd-plat-i2s";
			reg		= <0x0 0x02901000 0x0 0x7C>;
			resets		= <&ccu RST_BUS_I2S1>;
			clocks		= <&ccu CLK_BUS_I2S1_APB>,
					  <&ccu CLK_PLL_PERI0_200M>,
					  <&ccu CLK_PLL_AUDIO0>,
					  <&ccu CLK_PLL_AUDIO1_2X>,
					  <&ccu CLK_PLL_AUDIO1_5X>,
					  <&ccu CLK_I2S1>;
			clock-names	= "clk_bus_i2s",
					  "clk_pll_peri0_200m",
					  "clk_pll_audio0",
					  "clk_pll_audio1_2x",
					  "clk_pll_audio1_5x",
					  "clk_i2s";
			dmas		= <&dma 4>, <&dma 4>;
			dma-names	= "tx", "rx";
			playback-cma	= <128>;
			capture-cma	= <128>;
			tx-fifo-size	= <128>;
			rx-fifo-size	= <128>;
			status = "disabled";
		};

		i2s1_mach:i2s1_mach{
			compatible = "allwinner,sunxi-snd-mach";
			soundcard-mach,name		= "sndi2s1";
			soundcard-mach,format		= "i2s";
			soundcard-mach,slot-num		= <2>;
			soundcard-mach,slot-width	= <32>;
			status = "disabled";
			soundcard-mach,cpu {
				sound-dai = <&i2s1_plat>;
			};
			soundcard-mach,codec {
			};
		};

		i2s2_plat:i2s2_plat@2902000 {
			#sound-dai-cells = <0>;
			compatible = "allwinner,sunxi-snd-plat-i2s";
			reg		= <0x0 0x02902000 0x0 0x7C>;
			resets		= <&ccu RST_BUS_I2S2>;
			clocks		= <&ccu CLK_BUS_I2S2_APB>,
					  <&ccu CLK_PLL_PERI0_200M>,
					  <&ccu CLK_PLL_AUDIO0>,
					  <&ccu CLK_PLL_AUDIO1_2X>,
					  <&ccu CLK_PLL_AUDIO1_5X>,
					  <&ccu CLK_I2S2>;
			clock-names	= "clk_bus_i2s",
					  "clk_pll_peri0_200m",
					  "clk_pll_audio0",
					  "clk_pll_audio1_2x",
					  "clk_pll_audio1_5x",
					  "clk_i2s";
			dmas		= <&dma 5>, <&dma 5>;
			dma-names	= "tx", "rx";
			playback-cma	= <128>;
			capture-cma	= <128>;
			tx-fifo-size	= <128>;
			rx-fifo-size	= <128>;
			status = "disabled";
		};

		i2s2_mach:i2s2_mach{
			compatible = "allwinner,sunxi-snd-mach";
			/* card name. hdmi: "sndhdmi"; edp: "sndedp" */
			soundcard-mach,name		= "sndhdmi";
			soundcard-mach,format		= "i2s";
			soundcard-mach,slot-num		= <2>;
			soundcard-mach,slot-width	= <32>;
			status = "disabled";
			soundcard-mach,cpu {
				sound-dai = <&i2s2_plat>;
			};
			soundcard-mach,codec {
			};
		};

		i2s3_plat:i2s3_plat@2903000 {
			#sound-dai-cells = <0>;
			compatible = "allwinner,sunxi-snd-plat-i2s";
			reg		= <0x0 0x02903000 0x0 0x7C>;
			resets		= <&ccu RST_BUS_I2S3>;
			clocks		= <&ccu CLK_BUS_I2S3_APB>,
					  <&ccu CLK_PLL_PERI0_200M>,
					  <&ccu CLK_PLL_AUDIO0>,
					  <&ccu CLK_PLL_AUDIO1_2X>,
					  <&ccu CLK_PLL_AUDIO1_5X>,
					  <&ccu CLK_I2S3>;
			clock-names	= "clk_bus_i2s",
					  "clk_pll_peri0_200m",
					  "clk_pll_audio0",
					  "clk_pll_audio1_2x",
					  "clk_pll_audio1_5x",
					  "clk_i2s";
			dmas		= <&dma 6>, <&dma 6>;
			dma-names	= "tx", "rx";
			playback-cma	= <128>;
			capture-cma	= <128>;
			tx-fifo-size	= <128>;
			rx-fifo-size	= <128>;
			status = "disabled";
		};

		i2s3_mach:i2s3_mach{
			compatible = "allwinner,sunxi-snd-mach";
			soundcard-mach,name		= "sndi2s3";
			soundcard-mach,format		= "i2s";
			soundcard-mach,slot-num		= <2>;
			soundcard-mach,slot-width	= <32>;
			status = "disabled";
			soundcard-mach,cpu {
				sound-dai = <&i2s3_plat>;
			};
			soundcard-mach,codec {
			};
		};

		g2d: g2d@5440000 {
			compatible = "allwinner,sunxi-g2d";
			reg = <0x0 0x05440000 0x0 0x30000>;
			interrupts = <GIC_SPI 148 IRQ_TYPE_LEVEL_HIGH>;
			clocks = <&ccu CLK_BUS_G2D_AHB>, <&ccu CLK_G2D>;
			clock-names = "ahb_g2d", "g2d";
			resets = <&ccu RST_BUS_G2D>;
			iommus = <&mmu_aw 4 1>;
			assigned-clocks = <&ccu CLK_G2D>;
			assigned-clock-rates = <300000000>;
		};

		psci {
			compatible = "arm,psci-1.0";
			method = "smc";
		};

		timer0: timer0@3208000{
			compatible = "allwinner,hstimer-v100";
			device_type = "timer0";
			reg = <0x0 0x03208000 0x0 0x400>;
			interrupt-parent = <&gic>;
			interrupts = <GIC_SPI 112 IRQ_TYPE_LEVEL_HIGH>;
			clock-names = "parent", "bus", "timer0-mod", "timer1-mod";
			clocks = <&dcxo24M>, <&ccu CLK_BUS_TIMER0_AHB>, <&ccu CLK_TIMER0_0>, <&ccu CLK_TIMER0_1>;
			resets = <&ccu RST_BUS_TIMER0>;
		};

		pcie: pcie@c800000 {
			#address-cells = <3>;
			#size-cells = <2>;
			compatible = "allwinner,sun65iw1-pcie", "snps,dw-pcie";
			device_type = "pci";
			reg = <0x0 0x0c800000 0x0 0x00100000>,
			      <0x0 0x0c900000 0x0 0x00040000>,
			      <0x0 0x0cb00000 0x0 0x00080000>,
			      <0x0 0x0cb80000 0x0 0x00080000>,
			      <0x0 0x0cc00000 0x0 0x00080000>,
			      <0x4 0x40000000 0x0 0x01000000>;
			reg-names = "dbi", "dbi2", "atu", "dma", "app", "config";
			ranges = <0x01000000 0x4 0x41000000 0x4 0x41000000 0x0 0x01000000>, /* downstream I/O (16 MB) */
				 <0x02000000 0x0 0x22000000 0x4 0x42000000 0x0 0x08000000>, /* non-prefetchable memory (128 MB) */
				 <0x43000000 0x4 0x4a000000 0x4 0x4a000000 0x0 0xf6000000>; /* prefetchable memory (3936 MB) */
			clocks = <&ccu CLK_PCIE0_AUX>, <&ccu CLK_PCIE0_AXI_S>;
			clock-names = "aux", "axi_slv";
			assigned-clocks = <&ccu CLK_PCIE0_AXI_S>;
			assigned-clocks-parents = <&ccu CLK_PLL_PERI0_400M>;
			assigned-clock-rates = <400000000>;
			resets = <&ccu RST_BUS_PCIE0>, <&ccu RST_BUS_PCIE0_PWR_UP>;
			reset-names = "rst", "pwrup_rst";
			power-domains = <&pd SUN65IW1_PCK_HSI>;
			interrupts = <GIC_SPI 194 IRQ_TYPE_LEVEL_HIGH>,
				     <GIC_SPI 195 IRQ_TYPE_LEVEL_HIGH>,
				     <GIC_SPI 186 IRQ_TYPE_LEVEL_HIGH>,
				     <GIC_SPI 187 IRQ_TYPE_LEVEL_HIGH>;
			interrupt-names = "sii", "msi",
					  "dma0", /* edma-w */
					  "dma1"; /* edma-r */
			#interrupt-cells = <1>;
			interrupt-map-mask = <0 0 0 7>;
			interrupt-map = <0 0 0 1 &pcie_intc 0>,
					<0 0 0 2 &pcie_intc 1>,
					<0 0 0 3 &pcie_intc 2>,
					<0 0 0 4 &pcie_intc 3>;
			bus-range = <0x0 0xff>;
			linux,pci-domain = <0>;
			max-link-speed = <2>;
			num-lanes = <1>;
			phys = <&combo0_pcie>;
			phy-names = "pcie-phy";
			status = "disabled";

			pcie_intc: legacy-interrupt-controller {
				interrupt-controller;
				#address-cells = <0>;
				#interrupt-cells = <1>;
				interrupt-parent = <&gic>;
				interrupts = <GIC_SPI 194 IRQ_TYPE_EDGE_RISING>;
			};
		};

		gmac_stmmac_axi_setup: stmmac-axi-config {
			snps,wr_osr_lmt = <0xf>;
			snps,rd_osr_lmt = <0xf>;
			snps,blen = <256 128 64 32 16 8 4>;
		};

		gmac_mtl_rx_setup: rx-queues-config {
			snps,rx-queues-to-use = <1>;
			queue0 {};
		};

		gmac_mtl_tx_setup: tx_queues-config {
			snps,tx-queues-to-use = <1>;
			queue0 {};
		};

		gmac0: ethernet@de00000 {
			compatible = "allwinner,sunxi-gmac-110", "snps,dwmac-5.20";
			reg = <0x0 0x0de00000 0x0 0x8000>, /* ip */
				  <0x0 0x0de08000 0x0 0x1000>; /* cfg */
			interrupts = <GIC_SPI 170 IRQ_TYPE_LEVEL_HIGH>,
						<GIC_SPI 172 IRQ_TYPE_LEVEL_HIGH>, <GIC_SPI 173 IRQ_TYPE_LEVEL_HIGH>;
			interrupt-names = "macirq", "tx0_irq", "rx0_irq";
			clocks = <&ccu CLK_GMAC0_AXI>, <&ccu CLK_BUS_GMAC0_AHB>, <&ccu CLK_GMAC0_PHY>,
					<&ccu CLK_HSI_AXI>, <&ccu CLK_BUS_HSI_AHB>, <&ccu CLK_BUS_HSI_AXI>;
			clock-names = "stmmaceth", "pclk", "phy", "nsi", "hsi_ahb", "hsi_axi";
			assigned-clocks = <&ccu CLK_HSI_AXI>, <&ccu CLK_GMAC0_PHY>;
			assigned-clock-parents = <&ccu CLK_PLL_PERI0_480M>;
			assigned-clock-rates = <480000000>, <25000000>;
			resets = <&ccu RST_BUS_GMAC0_AXI>, <&ccu RST_BUS_GMAC0_AHB>, <&ccu RST_BUS_HSI_SY>;
			reset-names = "stmmaceth", "ahb", "hsi";
			phy-mode = "rgmii";
			phy-handle = <&gmac0_phy0>;
			power-domains = <&pd SUN65IW1_PCK_HSI>;
			status = "disabled";

			snps,fixed-burst;
			snps,axi-config = <&gmac_stmmac_axi_setup>;
			snps,mtl-rx-config = <&gmac_mtl_rx_setup>;
			snps,mtl-tx-config = <&gmac_mtl_tx_setup>;

			mdio0: mdio0@0 {
				compatible = "snps,dwmac-mdio";
				#address-cells = <1>;
				#size-cells = <0>;
				gmac0_phy0: ethernet-phy@0 {
					compatible = "ethernet-phy-ieee802.3-c22";
					reg = <0x1>;
					max-speed = <1000>;  /* Max speed capability */
					reset-gpios = <&pio PA 14 GPIO_ACTIVE_LOW>;
					/* PHY datasheet rst time */
					reset-assert-us = <10000>;
					reset-deassert-us = <150000>;
				};
			};
		};

		vind0: vind@4800800 {
			compatible = "allwinner,sunxi-vin-media", "simple-bus";
			#address-cells = <2>;
			#size-cells = <2>;
			ranges;
			device_id = <0>;
			csi_top = <336000000>;
			csi_isp = <327000000>;
			reg = <0x0 0x04800800 0x0 0x200>,
				<0x0 0x04800000 0x0 0x800>,
				<0x0 0x04810000 0x0 0x100>;
			interrupts = <GIC_SPI 220 IRQ_TYPE_LEVEL_HIGH>;
			clocks = <&ccu CLK_CSI>, <&ccu CLK_PLL_VIDEO2_4X>,
				<&ccu CLK_CSI_MASTER0>, <&dcxo24M>, <&ccu CLK_PLL_VIDEO1_4X>,
				<&ccu CLK_CSI_MASTER1>, <&dcxo24M>, <&ccu CLK_PLL_VIDEO1_4X>,
				<&ccu CLK_CSI_MASTER2>, <&dcxo24M>, <&ccu CLK_PLL_VIDEO1_4X>,
				<&ccu CLK_ISP>, <&ccu CLK_PLL_VIDEO0_4X>,
				<&ccu CLK_BUS_VIDEO_IN_AHB>, <&ccu CLK_BUS_VIDEO_IN_AHB_SW>,
				<&ccu CLK_CIS_MBUS>, <&ccu CLK_ISP_MBUS>, <&ccu CLK_MBUS_VIDEO_IN>;
			clock-names = "csi_top", "csi_top_src",
						"csi_mclk0", "csi_mclk0_24m", "csi_mclk0_pll",
						"csi_mclk1", "csi_mclk1_24m", "csi_mclk1_pll",
						"csi_mclk2", "csi_mclk2_24m", "csi_mclk2_pll",
						"csi_isp", "csi_isp_src",
						"csi_bus", "vid_in_ahb",
						"csi_mbus", "csi_isp_mbus", "vid_in_mbus";
			resets = <&ccu RST_BUS_VIDEO_IN>;
			reset-names = "csi_ret";
			pinctrl-names = "mclk0-default", "mclk0-sleep", "mclk1-default", "mclk1-sleep",
							"mclk2-default", "mclk2-sleep";
			pinctrl-0 = <&csi_mclk0_pins_a>;
			pinctrl-1 = <&csi_mclk0_pins_b>;
			pinctrl-2 = <&csi_mclk1_pins_a>;
			pinctrl-3 = <&csi_mclk1_pins_b>;
			pinctrl-4 = <&csi_mclk2_pins_a>;
			pinctrl-5 = <&csi_mclk2_pins_b>;
			power-domains = <&pd SUN65IW1_PCK_VI>;
			status = "okay";

			csi0: csi@4820000 {
				compatible = "allwinner,sunxi-csi";
				reg = <0x0 0x04820000 0x0 0x1000>;
				interrupts = <GIC_SPI 210 IRQ_TYPE_LEVEL_HIGH>;
				pinctrl-names = "default","sleep";
				pinctrl-0 = <&ncsi_bt656_pins_a>;
				pinctrl-1 = <&ncsi_bt656_pins_b>;
				device_id = <0>;
				status = "okay";
			};
			csi1: csi@4821000 {
				compatible = "allwinner,sunxi-csi";
				reg = <0x0 0x04821000 0x0 0x1000>;
				interrupts = <GIC_SPI 211 IRQ_TYPE_LEVEL_HIGH>;
				device_id = <1>;
				status = "okay";
			};
			csi2: csi@4822000 {
				compatible = "allwinner,sunxi-csi";
				reg = <0x0 0x04822000 0x0 0x1000>;
				interrupts = <GIC_SPI 212 IRQ_TYPE_LEVEL_HIGH>;
				device_id = <2>;
				status = "okay";
			};

			mipi0: mipi@4810100 {
				compatible = "allwinner,sunxi-mipi";
				reg = <0x0 0x04810100 0x0 0x100>,
					<0x0 0x04811000 0x0 0x400>,
					<0x0 0x03408240 0x0 0x10>,
					<0x0 0x03200174 0x0 0x10>;
				interrupts = <GIC_SPI 218 IRQ_TYPE_LEVEL_HIGH>;
				pinctrl-names = "mipi0-default","mipi0-sleep";
				pinctrl-0 = <&mipia_pins_a>;
				pinctrl-1 = <&mipia_pins_b>;
				device_id = <0>;
				status = "okay";
			};
			mipi1: mipi@4810200 {
				compatible = "allwinner,sunxi-mipi";
				reg = <0x0 0x04810200 0x0 0x100>,
					<0x0 0x04811400 0x0 0x400>;
				pinctrl-names = "mipi1-default","mipi1-sleep";
				pinctrl-0 = <&mipib_pins_a>;
				pinctrl-1 = <&mipib_pins_b>;
				pinctrl-2 = <&mipic_4lane_pins_a>;
				pinctrl-3 = <&mipic_4lane_pins_b>;
				device_id = <1>;
				status = "okay";
			};
			mipi2: mipi@4810300 {
				compatible = "allwinner,sunxi-mipi";
				reg = <0x0 0x04810300 0x0 0x100>,
					<0x0 0x04811800 0x0 0x400>;
				pinctrl-names = "mipi2-default","mipi2-sleep";
				pinctrl-0 = <&mipic_pins_a>;
				pinctrl-1 = <&mipic_pins_b>;
				device_id = <2>;
				status = "okay";
			};

			tdm0: tdm@4908000 {
				compatible = "allwinner,sunxi-tdm";
				reg = <0x0 0x04908000 0x0 0x400>;
				interrupts = <GIC_SPI 219 IRQ_TYPE_LEVEL_HIGH>;
				work_mode = <0x0>;
				device_id = <0>;
				iommus = <&mmu_aw 0 0>;
				status = "okay";
			};

			isp00:isp@4900000 {
				compatible = "allwinner,sunxi-isp";
				reg = <0x0 0x04900000 0x0 0x1300>;
				interrupts = <GIC_SPI 214 IRQ_TYPE_LEVEL_HIGH>;
				work_mode = <0x0>;
				device_id = <0>;
				iommus = <&mmu_aw 0 0>;
				status = "okay";
			};
			isp01:isp@48ffffc {
				compatible = "allwinner,sunxi-isp";
				reg = <0x0 0x048ffffc 0x0 0x1304>;
				interrupts = <GIC_SPI 215 IRQ_TYPE_LEVEL_HIGH>;
				work_mode = <0xff>;
				device_id = <1>;
				iommus = <&mmu_aw 0 0>;
				status = "disabled";
			};
			isp02:isp@48ffff8 {
				compatible = "allwinner,sunxi-isp";
				reg = <0x0 0x048ffff8 0x0 0x1308>;
				interrupts = <GIC_SPI 216 IRQ_TYPE_LEVEL_HIGH>;
				work_mode = <0xff>;
				device_id = <2>;
				iommus = <&mmu_aw 0 0>;
				status = "disabled";
			};
			isp03:isp@48ffff4 {
				compatible = "allwinner,sunxi-isp";
				reg = <0x0 0x048ffff4 0x0 0x130c>;
				interrupts = <GIC_SPI 217 IRQ_TYPE_LEVEL_HIGH>;
				work_mode = <0xff>;
				device_id = <3>;
				iommus = <&mmu_aw 0 0>;
				status = "disabled";
			};
			isp10:isp@4 {
				compatible = "allwinner,sunxi-isp";
				device_id = <4>;
				iommus = <&mmu_aw 0 0>;
				status = "disabled";
			};
			isp20:isp@5 {
				compatible = "allwinner,sunxi-isp";
				device_id = <5>;
				iommus = <&mmu_aw 0 0>;
				status = "disabled";
			};
			isp30:isp@6 {
				compatible = "allwinner,sunxi-isp";
				device_id = <6>;
				iommus = <&mmu_aw 0 0>;
				status = "disabled";
			};

			scaler00:scaler@4910000 {
				compatible = "allwinner,sunxi-scaler";
				reg = <0x0 0x04910000 0x0 0x400>;
				interrupts = <GIC_SPI 206 IRQ_TYPE_LEVEL_HIGH>;
				work_mode = <0x0>;
				device_id = <0>;
				iommus = <&mmu_aw 1 0>;
				status = "okay";
			};
			scaler01:scaler@490fffc {
				compatible = "allwinner,sunxi-scaler";
				reg = <0x0 0x0490fffc 0x0 0x404>;
				work_mode = <0xff>;
				device_id = <1>;
				iommus = <&mmu_aw 1 0>;
				status = "okay";
			};
			scaler02:scaler@490fff8 {
				compatible = "allwinner,sunxi-scaler";
				reg = <0x0 0x0490fff8 0x0 0x408>;
				work_mode = <0xff>;
				device_id = <2>;
				iommus = <&mmu_aw 1 0>;
				status = "okay";
			};
			scaler03:scaler@490fff4 {
				compatible = "allwinner,sunxi-scaler";
				reg = <0x0 0x0490fff4 0x0 0x40c>;
				work_mode = <0xff>;
				device_id = <3>;
				iommus = <&mmu_aw 1 0>;
				status = "okay";
			};
			scaler10:scaler@4910400 {
				compatible = "allwinner,sunxi-scaler";
				reg = <0x0 0x04910400 0x0 0x400>;
				interrupts = <GIC_SPI 207 IRQ_TYPE_LEVEL_HIGH>;
				work_mode = <0x0>;
				device_id = <4>;
				iommus = <&mmu_aw 1 0>;
				status = "okay";
			};
			scaler11:scaler@49103fc {
				compatible = "allwinner,sunxi-scaler";
				reg = <0x0 0x049103fc 0x0 0x404>;
				work_mode = <0xff>;
				device_id = <5>;
				iommus = <&mmu_aw 1 0>;
				status = "okay";
			};
			scaler12:scaler@49103f8 {
				compatible = "allwinner,sunxi-scaler";
				reg = <0x0 0x049103f8 0x0 0x408>;
				work_mode = <0xff>;
				device_id = <6>;
				iommus = <&mmu_aw 1 0>;
				status = "okay";
			};
			scaler13:scaler@49103f4 {
				compatible = "allwinner,sunxi-scaler";
				reg = <0x0 0x049103f4 0x0 0x40c>;
				work_mode = <0xff>;
				device_id = <7>;
				iommus = <&mmu_aw 1 0>;
				status = "okay";
			};
			scaler20:scaler@4910800 {
				compatible = "allwinner,sunxi-scaler";
				reg = <0x0 0x04910800 0x0 0x400>;
				interrupts = <GIC_SPI 208 IRQ_TYPE_LEVEL_HIGH>;
				work_mode = <0x0>;
				device_id = <8>;
				iommus = <&mmu_aw 1 0>;
				status = "okay";
			};
			scaler21:scaler@49107fc {
				compatible = "allwinner,sunxi-scaler";
				reg = <0x0 0x049107fc 0x0 0x404>;
				work_mode = <0xff>;
				device_id = <9>;
				iommus = <&mmu_aw 1 0>;
				status = "okay";
			};
			scaler22:scaler@49107f8 {
				compatible = "allwinner,sunxi-scaler";
				reg = <0x0 0x049107f8 0x0 0x408>;
				work_mode = <0xff>;
				device_id = <10>;
				iommus = <&mmu_aw 1 0>;
				status = "okay";
			};
			scaler23:scaler@49107f4 {
				compatible = "allwinner,sunxi-scaler";
				reg = <0x0 0x049107f4 0x0 0x40c>;
				work_mode = <0xff>;
				device_id = <11>;
				iommus = <&mmu_aw 1 0>;
				status = "okay";
			};
			scaler30:scaler@4910c00 {
				compatible = "allwinner,sunxi-scaler";
				reg = <0x0 0x04910c00 0x0 0x400>;
				interrupts = <GIC_SPI 209 IRQ_TYPE_LEVEL_HIGH>;
				work_mode = <0x0>;
				device_id = <12>;
				iommus = <&mmu_aw 1 0>;
				status = "okay";
			};
			scaler31:scaler@4910bfc {
				compatible = "allwinner,sunxi-scaler";
				reg = <0x0 0x04910bfc 0x0 0x404>;
				work_mode = <0xff>;
				device_id = <13>;
				iommus = <&mmu_aw 1 0>;
				status = "okay";
			};
			scaler32:scaler@4910bf8 {
				compatible = "allwinner,sunxi-scaler";
				reg = <0x0 0x04910bf8 0x0 0x408>;
				work_mode = <0xff>;
				device_id = <14>;
				iommus = <&mmu_aw 1 0>;
				status = "okay";
			};
			scaler33:scaler@4910bf4 {
				compatible = "allwinner,sunxi-scaler";
				reg = <0x0 0x04910bf4 0x0 0x40c>;
				work_mode = <0xff>;
				device_id = <15>;
				iommus = <&mmu_aw 1 0>;
				status = "okay";
			};

			actuator0: actuator@2108180 {
				compatible = "allwinner,sunxi-actuator";
				device_type = "actuator0";
				reg = <0x0 0x02108180 0x0 0x10>;
				actuator0_name = "ad5820_act";
				actuator0_slave = <0x18>;
				actuator0_af_pwdn = <>;
				actuator0_afvdd = "afvcc-csi";
				actuator0_afvdd_vol = <2800000>;
				status = "disabled";
			};
			flash0: flash@2108190 {
				device_type = "flash0";
				compatible = "allwinner,sunxi-flash";
				reg = <0x0 0x02108190 0x0 0x10>;
				flash0_type = <2>;
				flash0_en = <>;
				flash0_mode = <>;
				flash0_flvdd = "";
				flash0_flvdd_vol = <>;
				device_id = <0>;
				status = "disabled";
			};

			sensor0: sensor@4812000 {
				reg = <0x0 0x04812000 0x0 0x10>;
				device_type = "sensor0";
				compatible = "allwinner,sunxi-sensor";
				sensor0_mname = "ov5640";
				sensor0_twi_cci_id = <2>;
				sensor0_twi_addr = <0x78>;
				sensor0_mclk_id = <0>;
				sensor0_pos = "rear";
				sensor0_isp_used = <0>;
				sensor0_fmt = <0>;
				sensor0_stby_mode = <0>;
				sensor0_vflip = <0>;
				sensor0_hflip = <0>;
				sensor0_iovdd-supply = <>;
				sensor0_iovdd_vol = <>;
				sensor0_avdd-supply = <>;
				sensor0_avdd_vol = <>;
				sensor0_dvdd-supply = <>;
				sensor0_dvdd_vol = <>;
				sensor0_power_en = <>;
				sensor0_reset = <>;
				sensor0_pwdn = <>;
				sensor0_sm_vs = <>;
				flash_handle = <&flash0>;
				act_handle = <&actuator0>;
				device_id = <0>;
				status	= "disabled";
			};
			sensor1: sensor@4812010 {
				reg = <0x0 0x04812010 0x0 0x10>;
				device_type = "sensor1";
				compatible = "allwinner,sunxi-sensor";
				sensor1_mname = "ov5647";
				sensor1_twi_cci_id = <3>;
				sensor1_twi_addr = <0x6c>;
				sensor1_mclk_id = <1>;
				sensor1_pos = "front";
				sensor1_isp_used = <0>;
				sensor1_fmt = <0>;
				sensor1_stby_mode = <0>;
				sensor1_vflip = <0>;
				sensor1_hflip = <0>;
				sensor1_iovdd-supply = <>;
				sensor1_iovdd_vol = <>;
				sensor1_avdd-supply = <>;
				sensor1_avdd_vol = <>;
				sensor1_dvdd-supply = <>;
				sensor1_dvdd_vol = <>;
				sensor1_power_en = <>;
				sensor1_reset = <>;
				sensor1_pwdn = <>;
				sensor1_sm_vs = <>;
				flash_handle = <>;
				act_handle = <>;
				device_id = <1>;
				status	= "disabled";
			};
			sensor2: sensor@4812020 {
				reg = <0x0 0x04812020 0x0 0x10>;
				device_type = "sensor2";
				compatible = "allwinner,sunxi-sensor";
				sensor2_mname = "imx386_mipi";
				sensor2_twi_cci_id = <3>;
				sensor2_twi_addr = <0x6c>;
				sensor2_mclk_id = <1>;
				sensor2_pos = "rear";
				sensor2_isp_used = <0>;
				sensor2_fmt = <0>;
				sensor2_stby_mode = <0>;
				sensor2_vflip = <0>;
				sensor2_hflip = <0>;
				sensor2_iovdd-supply = <>;
				sensor2_iovdd_vol = <>;
				sensor2_avdd-supply = <>;
				sensor2_avdd_vol = <>;
				sensor2_dvdd-supply = <>;
				sensor2_dvdd_vol = <>;
				sensor2_power_en = <>;
				sensor2_reset = <>;
				sensor2_pwdn = <>;
				sensor2_sm_vs = <>;
				flash_handle = <>;
				act_handle = <>;
				device_id = <2>;
				status= "disabled";
			};

			sensor_list0:sensor_list@4812040 {
				reg = <0x0 0x04812040 0x0 0x10>;
				device_type = "sensor_list0";
				compatible = "allwinner,sunxi-sensor-list";
				csi_sel = <0>;
				sensor00_mname = "ov5675_mipi_b";
				sensor00_twi_addr = <0x60>;
				sensor00_type = <1>;
				sensor00_hflip =  <1>;
				sensor00_vflip = <0>;
				sensor00_act_used = <1>;
				sensor00_act_name = "dw9714_act";
				sensor00_act_twi_addr = <0x18>;
				sensor01_mname = "gc05a2_mipi_b";
				sensor01_twi_addr = <0x62>;
				sensor01_type = <1>;
				sensor01_hflip =  <0>;
				sensor01_vflip = <0>;
				sensor01_act_used = <1>;
				sensor01_act_name = "dw9714_act";
				sensor01_act_twi_addr = <0x18>;
				sensor02_mname = "gc5035_mipi_b";
				sensor02_twi_addr = <0x64>;
				sensor02_type = <1>;
				sensor02_hflip =  <0>;
				sensor02_vflip = <0>;
				sensor02_act_used = <1>;
				sensor02_act_name = "dw9714_act";
				sensor02_act_twi_addr = <0x18>;
				device_id = <0>;
				status	= "disabled";
			};
			sensor_list1:sensor_list@4812050 {
				reg = <0x0 0x04812050 0x0 0x10>;
				device_type = "sensor_list1";
				compatible = "allwinner,sunxi-sensor-list";
				csi_sel = <0>;
				sensor10_mname = "ov02a10_mipi_f";
				sensor10_twi_addr = <0x70>;
				sensor10_type = <1>;
				sensor10_hflip =  <1>;
				sensor10_vflip = <0>;
				sensor10_act_used = <0>;
				sensor10_act_name = "";
				sensor10_act_twi_addr = <>;
				sensor11_mname = "gc02m1_mipi_f";
				sensor11_twi_addr = <0x72>;
				sensor11_type = <1>;
				sensor11_hflip =  <1>;
				sensor11_vflip = <0>;
				sensor11_act_used = <0>;
				sensor11_act_name = "";
				sensor11_act_twi_addr = <>;
				sensor12_mname = "gc02m2_mipi_f";
				sensor12_twi_addr = <0x74>;
				sensor12_type = <1>;
				sensor12_hflip =  <0>;
				sensor12_vflip = <0>;
				sensor12_act_used = <0>;
				sensor12_act_name = "";
				sensor12_act_twi_addr = <>;
				device_id = <1>;
				status	= "disabled";
			};

			vinc00:vinc@4830000 {
				device_type = "vinc0";
				compatible = "allwinner,sunxi-vin-core";
				reg = <0x0 0x04830000 0x0 0x1000>;
				interrupts = <GIC_SPI 202 IRQ_TYPE_LEVEL_HIGH>;
				vinc0_csi_sel = <0>;
				vinc0_mipi_sel = <0xff>;
				vinc0_isp_sel = <0>;
				vinc0_isp_tx_ch = <0>;
				vinc0_tdm_rx_sel = <0>;
				vinc0_rear_sensor_sel = <0>;
				vinc0_front_sensor_sel = <0>;
				vinc0_sensor_list = <0>;
				device_id = <0>;
				work_mode = <0x0>;
				iommus = <&mmu_aw 1 0>;
				status = "okay";
			};

			vinc01:vinc@482fffc {
				device_type = "vinc1";
				compatible = "allwinner,sunxi-vin-core";
				reg = <0x0 0x0482fffc 0x0 0x1004>;
				vinc1_csi_sel = <2>;
				vinc1_mipi_sel = <0xff>;
				vinc1_isp_sel = <1>;
				vinc1_isp_tx_ch = <1>;
				vinc1_tdm_rx_sel = <1>;
				vinc1_rear_sensor_sel = <0>;
				vinc1_front_sensor_sel = <0>;
				vinc1_sensor_list = <0>;
				device_id = <1>;
				work_mode = <0xff>;
				iommus = <&mmu_aw 1 0>;
				status = "disabled";
			};
			vinc02:vinc@482fff8 {
				device_type = "vinc2";
				compatible = "allwinner,sunxi-vin-core";
				reg = <0x0 0x0482fff8 0x0 0x1008>;
				vinc2_csi_sel = <2>;
				vinc2_mipi_sel = <0xff>;
				vinc2_isp_sel = <2>;
				vinc2_isp_tx_ch = <2>;
				vinc2_tdm_rx_sel = <2>;
				vinc2_rear_sensor_sel = <0>;
				vinc2_front_sensor_sel = <0>;
				vinc2_sensor_list = <0>;
				device_id = <2>;
				work_mode = <0xff>;
				iommus = <&mmu_aw 1 0>;
				status = "disabled";
			};

			vinc03:vinc@482fff4 {
				device_type = "vinc3";
				compatible = "allwinner,sunxi-vin-core";
				reg = <0x0 0x0482fff4 0x0 0x100c>;
				vinc3_csi_sel = <0>;
				vinc3_mipi_sel = <0xff>;
				vinc3_isp_sel = <0>;
				vinc3_isp_tx_ch = <0>;
				vinc3_tdm_rx_sel = <0>;
				vinc3_rear_sensor_sel = <1>;
				vinc3_front_sensor_sel = <1>;
				vinc3_sensor_list = <0>;
				device_id = <3>;
				work_mode = <0xff>;
				iommus = <&mmu_aw 1 0>;
				status = "disabled";
			};

			vinc10:vinc@4831000 {
				device_type = "vinc4";
				compatible = "allwinner,sunxi-vin-core";
				reg = <0x0 0x04831000 0x0 0x1000>;
				interrupts = <GIC_SPI 203 IRQ_TYPE_LEVEL_HIGH>;
				vinc4_csi_sel = <3>;
				vinc4_mipi_sel = <0xff>;
				vinc4_isp_sel = <0>;
				vinc4_isp_tx_ch = <0>;
				vinc4_tdm_rx_sel = <1>;
				vinc4_rear_sensor_sel = <0>;
				vinc4_front_sensor_sel = <0>;
				vinc4_sensor_list = <0>;
				device_id = <4>;
				work_mode = <0x0>;
				iommus = <&mmu_aw 1 0>;
				status = "disabled";
			};

			vinc11:vinc@4830ffc {
				device_type = "vinc5";
				compatible = "allwinner,sunxi-vin-core";
				reg = <0x0 0x04830ffc 0x0 0x1004>;
				vinc5_csi_sel = <2>;
				vinc5_mipi_sel = <0xff>;
				vinc5_isp_sel = <1>;
				vinc5_isp_tx_ch = <1>;
				vinc5_tdm_rx_sel = <1>;
				vinc5_rear_sensor_sel = <0>;
				vinc5_front_sensor_sel = <0>;
				vinc5_sensor_list = <0>;
				device_id = <5>;
				work_mode = <0xff>;
				iommus = <&mmu_aw 1 0>;
				status = "disabled";
			};

			vinc12:vinc@4830ff8 {
				device_type = "vinc6";
				compatible = "allwinner,sunxi-vin-core";
				reg = <0x0 0x04830ff8 0x0 0x1008>;
				vinc6_csi_sel = <2>;
				vinc6_mipi_sel = <0xff>;
				vinc6_isp_sel = <0>;
				vinc6_isp_tx_ch = <0>;
				vinc6_tdm_rx_sel = <0>;
				vinc6_rear_sensor_sel = <0>;
				vinc6_front_sensor_sel = <0>;
				vinc6_sensor_list = <0>;
				device_id = <6>;
				work_mode = <0xff>;
				iommus = <&mmu_aw 1 0>;
				status = "disabled";
			};

			vinc13:vinc@4830ff4 {
				device_type = "vinc7";
				compatible = "allwinner,sunxi-vin-core";
				reg = <0x0 0x04830ff4 0x0 0x100c>;
				vinc7_csi_sel = <2>;
				vinc7_mipi_sel = <0xff>;
				vinc7_isp_sel = <0>;
				vinc7_isp_tx_ch = <0>;
				vinc7_tdm_rx_sel = <0>;
				vinc7_rear_sensor_sel = <0>;
				vinc7_front_sensor_sel = <0>;
				vinc7_sensor_list = <0>;
				device_id = <7>;
				work_mode = <0xff>;
				iommus = <&mmu_aw 1 0>;
				status = "disabled";
			};

			vinc20:vinc@4832000 {
				device_type = "vinc8";
				compatible = "allwinner,sunxi-vin-core";
				reg = <0x0 0x04832000 0x0 0x1000>;
				interrupts = <GIC_SPI 204 IRQ_TYPE_LEVEL_HIGH>;
				vinc8_csi_sel = <2>;
				vinc8_mipi_sel = <0xff>;
				vinc8_isp_sel = <4>;
				vinc8_isp_tx_ch = <3>;
				vinc8_tdm_rx_sel = <3>;
				vinc8_rear_sensor_sel = <0>;
				vinc8_front_sensor_sel = <0>;
				vinc8_sensor_list = <0>;
				device_id = <8>;
				work_mode = <0x0>;
				iommus = <&mmu_aw 1 0>;
				status = "disabled";
			};

			vinc21:vinc@4831ffc {
				device_type = "vinc9";
				compatible = "allwinner,sunxi-vin-core";
				reg = <0x0 0x04831ffc 0x0 0x1004>;
				vinc9_csi_sel = <2>;
				vinc9_mipi_sel = <0xff>;
				vinc9_isp_sel = <0>;
				vinc9_isp_tx_ch = <0>;
				vinc9_tdm_rx_sel = <0>;
				vinc9_rear_sensor_sel = <0>;
				vinc9_front_sensor_sel = <0>;
				vinc9_sensor_list = <0>;
				device_id = <9>;
				work_mode = <0xff>;
				iommus = <&mmu_aw 1 0>;
				status = "disabled";
			};

			vinc22:vinc@4831ff8 {
				device_type = "vinc10";
				compatible = "allwinner,sunxi-vin-core";
				reg = <0x0 0x04831ff8 0x0 0x1008>;
				vinc10_csi_sel = <2>;
				vinc10_mipi_sel = <0xff>;
				vinc10_isp_sel = <0>;
				vinc10_isp_tx_ch = <0>;
				vinc10_tdm_rx_sel = <0>;
				vinc10_rear_sensor_sel = <0>;
				vinc10_front_sensor_sel = <0>;
				vinc10_sensor_list = <0>;
				device_id = <10>;
				work_mode = <0xff>;
				iommus = <&mmu_aw 1 0>;
				status = "disabled";
			};

			vinc23:vinc@4831ff4 {
				device_type = "vinc11";
				compatible = "allwinner,sunxi-vin-core";
				reg = <0x0 0x04831ff4 0x0 0x100c>;
				vinc11_csi_sel = <2>;
				vinc11_mipi_sel = <0xff>;
				vinc11_isp_sel = <0>;
				vinc11_isp_tx_ch = <0>;
				vinc11_tdm_rx_sel = <0>;
				vinc11_rear_sensor_sel = <0>;
				vinc11_front_sensor_sel = <0>;
				vinc11_sensor_list = <0>;
				device_id = <11>;
				work_mode = <0xff>;
				iommus = <&mmu_aw 1 0>;
				status = "disabled";
			};

			vinc30:vinc@4833000 {
				device_type = "vinc12";
				compatible = "allwinner,sunxi-vin-core";
				reg = <0x0 0x04833000 0x0 0x1000>;
				interrupts = <GIC_SPI 205 IRQ_TYPE_LEVEL_HIGH>;
				vinc12_csi_sel = <2>;
				vinc12_mipi_sel = <0xff>;
				vinc12_isp_sel = <0>;
				vinc12_isp_tx_ch = <0>;
				vinc12_tdm_rx_sel = <0>;
				vinc12_rear_sensor_sel = <0>;
				vinc12_front_sensor_sel = <0>;
				vinc12_sensor_list = <0>;
				device_id = <12>;
				work_mode = <0x0>;
				iommus = <&mmu_aw 1 0>;
				status = "disabled";
			};

			vinc31:vinc@4832ffc {
				device_type = "vinc13";
				compatible = "allwinner,sunxi-vin-core";
				reg = <0x0 0x04832ffc 0x0 0x1004>;
				vinc13_csi_sel = <2>;
				vinc13_mipi_sel = <0xff>;
				vinc13_isp_sel = <0>;
				vinc13_isp_tx_ch = <0>;
				vinc13_tdm_rx_sel = <0>;
				vinc13_rear_sensor_sel = <0>;
				vinc13_front_sensor_sel = <0>;
				vinc13_sensor_list = <0>;
				device_id = <13>;
				work_mode = <0xff>;
				iommus = <&mmu_aw 1 0>;
				status = "disabled";
			};

			vinc32:vinc@4832ff8 {
				device_type = "vinc14";
				compatible = "allwinner,sunxi-vin-core";
				reg = <0x0 0x04832ff8 0x0 0x1008>;
				vinc14_csi_sel = <2>;
				vinc14_mipi_sel = <0xff>;
				vinc14_isp_sel = <0>;
				vinc14_isp_tx_ch = <0>;
				vinc14_tdm_rx_sel = <0>;
				vinc14_rear_sensor_sel = <0>;
				vinc14_front_sensor_sel = <0>;
				vinc14_sensor_list = <0>;
				device_id = <14>;
				work_mode = <0xff>;
				iommus = <&mmu_aw 1 0>;
				status = "disabled";
			};

			vinc33:vinc@4832ff4 {
				device_type = "vinc15";
				compatible = "allwinner,sunxi-vin-core";
				reg = <0x0 0x04832ff4 0x0 0x100c>;
				vinc15_csi_sel = <2>;
				vinc15_mipi_sel = <0xff>;
				vinc15_isp_sel = <0>;
				vinc15_isp_tx_ch = <0>;
				vinc15_tdm_rx_sel = <0>;
				vinc15_rear_sensor_sel = <0>;
				vinc15_front_sensor_sel = <0>;
				vinc15_sensor_list = <0>;
				device_id = <15>;
				work_mode = <0xff>;
				iommus = <&mmu_aw 1 0>;
				status = "disabled";
			};
		};

		usbc0: usbc0@10 {
			device_type = "usbc0";
			compatible = "allwinner,sunxi-otg-manager";
			reg = <0x0 0x10 0x0 0x1000>;
			usb_port_type = <2>;
			usb_detect_type = <1>;
			usb_detect_mode = <0>;
			usb_id_gpio;
			usb_det_vbus_gpio;
			usb_regulator_io = "nocare";
			usb_wakeup_suspend = <0>;
			usb_luns = <3>;
			usb_serial_unique = <0>;
			usb_serial_number = "20080411";
			rndis_wceis = <1>;
			status = "disabled";
		};

		udc:udc-controller@c100000 {
			compatible = "allwinner,sunxi-udc";
			reg = <0x0 0x0c100000 0x0 0x1000>, /* udc base */
			      <0x0 0x00000000 0x0 0x100>;  /* sram base */
			interrupts = <GIC_SPI 68 IRQ_TYPE_LEVEL_HIGH>;
			clocks = <&ccu CLK_BUS_USB0_DEV_AHB>, <&ccu CLK_BUS_USB2P0_SYS_AHB>;
			clock-names = "bus_otg", "usb_sys_ahb";
			resets = <&ccu RST_USB0_DEV>, <&ccu RST_USB2P0_SY>;
			reset-names = "otg", "usb_rst";
			phys = <&u2phy0>;
			phy-names = "usb2-phy";
			aw,dma_addr_extend;
			aw,dma_wordaddr_bypass = <0x1>;
			status = "disabled";
		};

		ehci0:ehci0-controller@c101000 {
			compatible = "allwinner,sunxi-ehci0";
			reg = <0x0 0x0c101000 0x0 0xFFF>,  /*hci0 base*/
			      <0x0 0x00000000 0x0 0x100>,  /*sram base*/
			      <0x0 0x0c100000 0x0 0x1000>; /*otg base*/
			interrupts = <GIC_SPI 69 IRQ_TYPE_LEVEL_HIGH>;
			clocks = <&ccu CLK_BUS_USB0_EHCI_AHB>, <&ccu CLK_BUS_USB2P0_SYS_AHB>;
			clock-names = "bus_hci", "usb_sys_ahb";
			resets = <&ccu RST_USB0_EHCI>,  <&ccu RST_USB2P0_SY>;
			reset-names = "hci", "usb_rst";
			hci_ctrl_no = <0>;
			phys = <&u2phy0>;
			phy-names = "usb2-phy";
			status = "disabled";
		};

		ohci0:ohci0-controller@c101400 {
			compatible = "allwinner,sunxi-ohci0";
			reg = <0x0 0x0c101400 0x0 0xFFF>,  /*hci0 base*/
			      <0x0 0x00000000 0x0 0x100>,  /*sram base*/
			      <0x0 0x0c100000 0x0 0x1000>; /*otg base*/
			interrupts = <GIC_SPI 70 IRQ_TYPE_LEVEL_HIGH>;
			clocks = <&ccu CLK_BUS_USB0_OHCI_AHB>, <&ccu CLK_BUS_USB0>, <&ccu CLK_BUS_USB2P0_SYS_AHB>;
			clock-names = "bus_hci", "ohci", "usb_sys_ahb";
			resets = <&ccu RST_USB0_OHCI>, <&ccu RST_USB2P0_SY>;
			reset-names = "hci", "usb_rst";
			hci_ctrl_no = <0>;
			phys = <&u2phy0>;
			phy-names = "usb2-phy";
			status = "disabled";
		};

		usbc1: usbc1@11 {
			device_type = "usbc1";
			reg = <0x0 0x11 0x0 0x1000>;
			usb_regulator_io = "nocare";
			usb_wakeup_suspend = <0>;
			status = "disabled";
		};

		ehci1: ehci1-controller@c200000 {
			compatible = "allwinner,sunxi-ehci1";
			reg = <0x0 0x0c200000 0x0 0xFFF>,  /*ehci1 base*/
			      <0x0 0x00000000 0x0 0x100>,  /*sram base*/
			      <0x0 0x0c100000 0x0 0x1000>; /*otg base*/
			interrupts = <GIC_SPI 71 IRQ_TYPE_LEVEL_HIGH>;
			clocks = <&ccu CLK_BUS_USB1_EHCI_AHB>, <&ccu CLK_BUS_USB2P0_SYS_AHB>;
			clock-names = "bus_hci", "usb_sys_ahb";
			resets = <&ccu RST_USB1_EHCI>, <&ccu RST_USB2P0_SY>;
			reset-names = "hci", "usb_rst";
			hci_ctrl_no = <1>;
			phys = <&u2phy1>;
			phy-names = "usb2-phy";
			status = "disabled";
		};

		ohci1: ohci1-controller@c200400 {
			compatible = "allwinner,sunxi-ohci1";
			reg = <0x0 0x0c200400 0x0 0xFFF>,  /*ohci1 base*/
			      <0x0 0x00000000 0x0 0x100>,  /*sram base*/
			      <0x0 0x0c100000 0x0 0x1000>; /*otg base*/
			interrupts = <GIC_SPI 72 IRQ_TYPE_LEVEL_HIGH>;
			clocks = <&ccu CLK_BUS_USB1_OHCI_AHB>, <&ccu CLK_BUS_USB1>, <&ccu CLK_BUS_USB2P0_SYS_AHB>;
			clock-names = "bus_hci", "ohci", "usb_sys_ahb";
			resets = <&ccu RST_USB1_OHCI>, <&ccu RST_USB2P0_SY>;
			reset-names = "hci", "usb_rst";
			hci_ctrl_no = <1>;
			phys = <&u2phy1>;
			phy-names = "usb2-phy";
			status = "disabled";
		};

		usbc2:usbc2@12 {
			device_type = "usbc2";
			compatible = "allwinner,sunxi-plat-dwc3";
			reg = <0x0 0x12 0x0 0x1000>;
			#address-cells = <2>;
			#size-cells = <2>;
			ranges;
			status = "disabled";

			xhci2: xhci2-controller@c400000 {
				compatible = "snps,dwc3";
				reg = <0x0 0x0c400000 0x0 0x100000>;
				interrupts = <GIC_SPI 73 IRQ_TYPE_LEVEL_HIGH>;
				dr_mode = "otg"; // dr_mode option: host, peripheral, otg
				clocks = <&ccu CLK_USB2_REF>, <&ccu CLK_BUS_USB2_U2_PHY_REF>, <&ccu CLK_USB2_SUSPEND>;
				clock-names = "bus_clk", "ref_clk", "suspend";
				assigned-clocks = <&ccu CLK_USB2_SUSPEND>;
				assigned-clock-rates = <24000000>;
				resets = <&ccu RST_USB2>;
				reset-names = "hci";
				maximum-speed = "super-speed";
				phy_type = "utmi";
				snps,dis_enblslpm_quirk;
				snps,dis-u1-entry-quirk;
				snps,dis-u2-entry-quirk;
				snps,dis_u3_susphy_quirk;
				snps,dis_u2_susphy_quirk;
				phys = <&u2phy2>, <&combo0_usb3>;
				phy-names = "usb2-phy", "usb3-phy";
				status = "disabled";
			};
		};

		synopsys: synopsys@dc80000 {
			compatible = "allwinner,synopsys-combophy-v2";
			reg = <0x0 0x0dc80000 0x0 0x8000>, /* HSI Subsystem Application Register */
			      <0x0 0x0dd00000 0x0 0x100>, /* COMBO0 PHY TOP Application Register */
			      <0x0 0x0dd01000 0x0 0x10>, /* COMBO0 PHY CORE Application Register */
			      <0x0 0x03200184 0x0 0x4>; /* EXT HSI_COMBO RES ohms Registers */
			clocks = <&ccu CLK_BUS_HSI_AHB_SW>, <&ccu CLK_HSI_AXI>,
				 <&ccu CLK_BUS_HSI_AHB>, <&ccu CLK_BUS_HSI_AXI>;
			clock-names = "bus_clk", "axi_clk",
				      "ahb_bus_clk", "axi_bus_clk";
			assigned-clocks = <&ccu CLK_HSI_AXI>;
			assigned-clock-rates = <600000000>;
			resets = <&ccu RST_BUS_HSI_SY>;
			reset-names = "reset";
			power-domains = <&pd SUN65IW1_PCK_HSI>;
			#address-cells = <2>;
			#size-cells = <2>;
			ranges;
			sid = <&sid>;
			sid-res = "res1";
			status = "disabled";

			combo0_usb3: combo-usb3 {
				clocks = <&ccu CLK_HSI_COMB0_PHY_REF>, <&ccu CLK_HSI_COMB0_PHY_CFG>,
					 <&ccu CLK_USB2_U3_ONLY_UTMI>;
				clock-names = "comb0_ref_clk", "comb0_cfg_clk", "u3_only_clk";
				#phy-cells = <0>;
				status = "okay";
			};

			combo0_pcie: combo-pcie {
				clocks = <&ccu CLK_HSI_COMB0_PHY_REF>, <&ccu CLK_HSI_COMB0_PHY_CFG>;
				clock-names = "comb0_ref_clk", "comb0_cfg_clk";
				#phy-cells = <0>;
				status = "okay";
			};
		};

		u2phy: phy@c000000 {
			compatible = "allwinner,sunxi-awphy-v100";
			reg = <0x0 0x0c000000 0x0 0x100>, /* PHY Application Registers */
			      <0x0 0x0c080000 0x0 0x100>, /* Digital Application Registers */
			      <0x0 0x03200178 0x0 0x4>; /* INT USB RES ohms Registers */
			reg-names = "phy_base", "top_base", "res_base";
			clocks = <&ccu CLK_BUS_HSI_AHB>, <&ccu CLK_BUS_HSI_AHB_SW>;
			clock-names = "mclk", "pclk";
			resets = <&ccu RST_BUS_HSI_SY>, <&ccu RST_USB2P0_SY>;
			reset-names = "rst", "usb_rst";
			#phy-cells = <0>;
			sid = <&sid>;
			sid-res = "res0";
			status = "disabled";

			u2phy0: u2-phy0 {
				clocks = <&ccu CLK_BUS_USB2P0_SYS_PHY_REF>;
				clock-names = "ref_clk";
				dpdm-bypass-quirk = <0x02 0xb2 0x00 0x01
						     0x02 0xb8 0x01 0x01
						     0x02 0xb9 0x01 0x01
						     0x02 0xba 0x00 0x01
						     0x02 0xbb 0x01 0x01>;
				#phy-cells = <0>;
				status = "okay";
			};

			u2phy1: u2-phy1 {
				clocks = <&ccu CLK_BUS_USB2P0_SYS_PHY_REF>;
				clock-names = "ref_clk";
				#phy-cells = <0>;
				status = "okay";
			};

			u2phy2: u2-phy2 {
				clocks = <&ccu CLK_BUS_USB2P0_SYS_PHY_REF>, <&ccu CLK_USB2_U2_ONLY_PIPE>;
				clock-names = "ref_clk", "u2_only_clk";
				dpdm-bypass-quirk = <0x02 0xb2 0x00 0x01
						     0x02 0xb8 0x01 0x01
						     0x02 0xb9 0x01 0x01
						     0x02 0xba 0x00 0x01
						     0x02 0xbb 0x01 0x01>;
				#phy-cells = <0>;
				status = "okay";
			};
		};

		rfkill: rfkill {
			compatible = "allwinner,sunxi-rfkill";
			status = "disabled";
		};

		addr_mgt: addr_mgt {
			compatible = "allwinner,sunxi-addr_mgt";
			status = "disabled";
		};

		btlpm: btlpm {
			compatible = "allwinner,sunxi-btlpm";
			status = "disabled";
		};

		timestamp: timestamp@8220000 {
			compatible = "allwinner,timestamp";
			reg = <0x0 0x08220000 0x0 0x8>;
			clocks = <&dcxo24M>;
			clock-names = "hosc";
			status = "okay";
		};
	};
};
